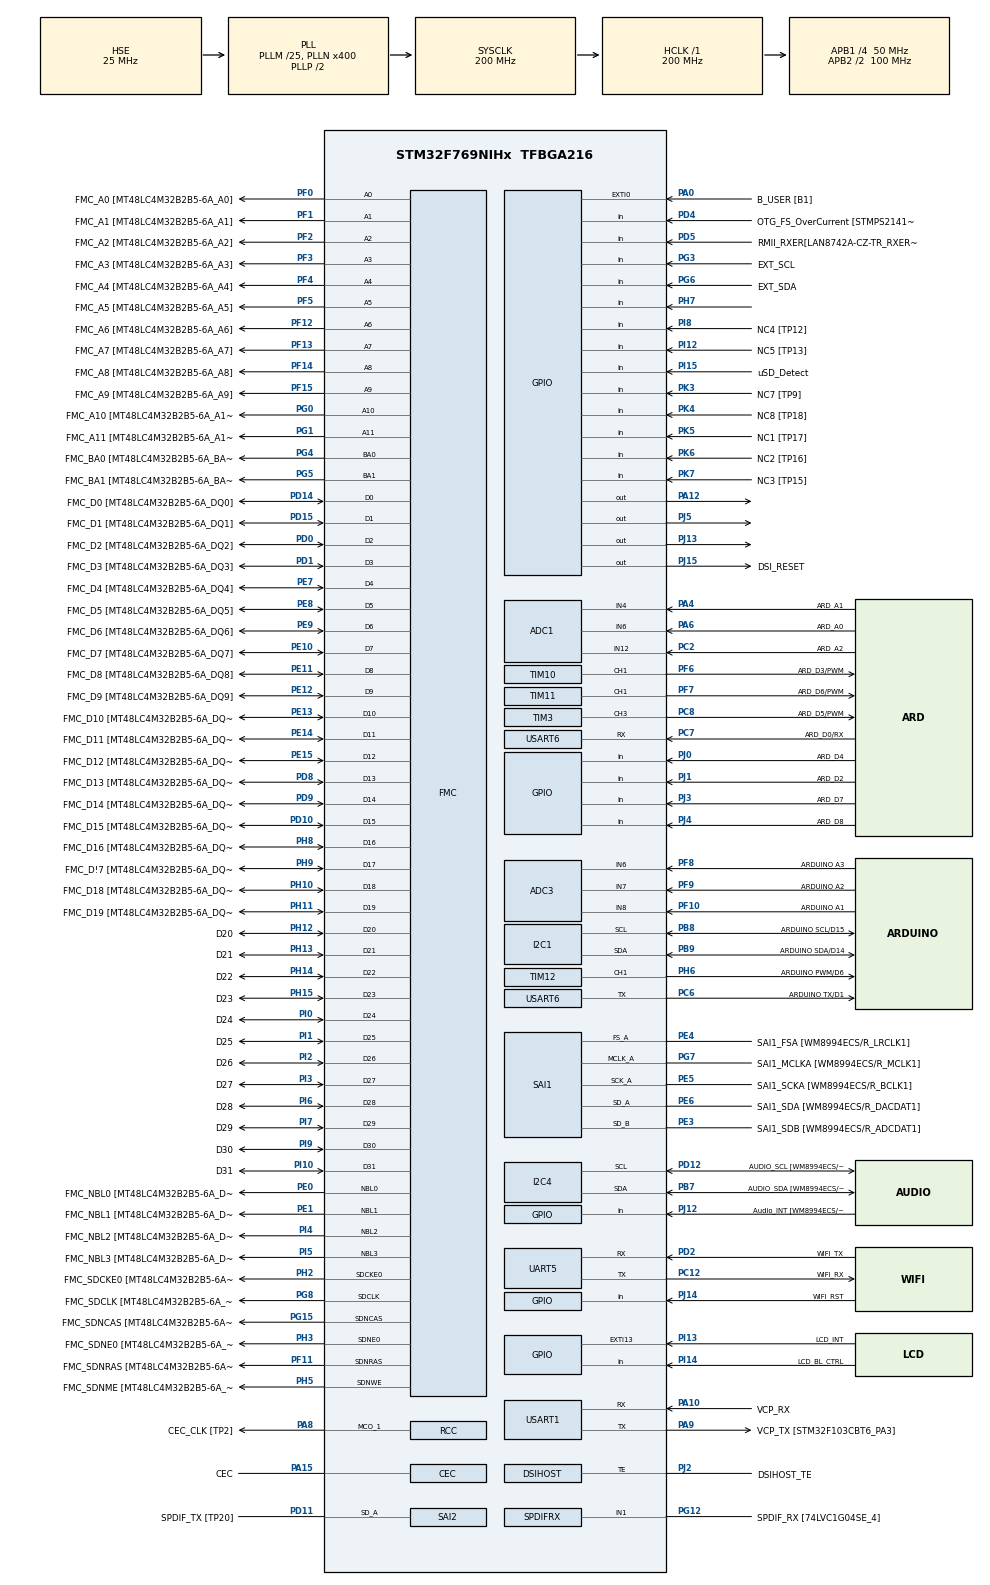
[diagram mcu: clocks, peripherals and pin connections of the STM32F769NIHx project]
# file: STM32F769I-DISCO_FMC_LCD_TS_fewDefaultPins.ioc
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PD12.GPIO_Label=AUDIO_SCL [WM8994ECS/R_SCLK]
FMC.SDClockPeriod1=FMC_SDRAM_CLOCK_PERIOD_2
SH.FMC_A0.0=FMC_A0,12b-sda1
PH15.GPIO_Label=D23
PG8.Signal=FMC_SDCLK
DSIHOST_D0N.Mode=DSIHost_Adapted_TE
PG0.Signal=FMC_A10
SAI1.Instance-SAI_A_MasterWithClock=SAI$Index_Block_A
PI15.GPIO_Label=uSD_Detect
SH.FMC_D5_DA5.0=FMC_D5,sd-32b-d1
PF10.GPIO_PuPd=GPIO_NOPULL
SH.FMC_D9_DA9.0=FMC_D9,sd-32b-d1
DSIHOST_D0P.Signal=DSIHOST_D0P
SH.FMC_D25.0=FMC_D25,sd-32b-d1
PG15.GPIO_Label=FMC_SDNCAS [MT48LC4M32B2B5-6A_CAS]
PF7.Signal=S_TIM11_CH1
NVIC.DMA2D_IRQn=true\:0\:0\:false\:false\:true\:true\:true
RCC.PLL48CLockSelection=RCC_CLK48SOURCE_PLLSAIP
SH.FMC_SDNWE.0=FMC_SDNWE,12b-sda1
PH9.Signal=FMC_D17
SH.FMC_D11_DA11.0=FMC_D11,sd-32b-d1
RTC.Alarm-AlarmA_RoutedAF=RTC_ALARM_A
RCC.APB2TimFreq_Value=200000000
PC7.Signal=USART6_RX
PD0.Signal=FMC_D2_DA2
PD8.Signal=FMC_D13_DA13
USART6.VirtualMode-Asynchronous=VM_ASYNC
PE1.Signal=FMC_NBL1
PB3.Mode=Trace_Asynchronous_SW
PF1.GPIO_Label=FMC_A1 [MT48LC4M32B2B5-6A_A1]
PI4.GPIO_Label=FMC_NBL2 [MT48LC4M32B2B5-6A_DQM2]
PK4.GPIO_Label=NC8 [TP18]
PD1.GPIO_Label=FMC_D3 [MT48LC4M32B2B5-6A_DQ3]
FMC.SelfRefreshTime1=4
PF12.GPIO_Label=FMC_A6 [MT48LC4M32B2B5-6A_A6]
LTDC.PixelFormat_L0=LTDC_PIXEL_FORMAT_RGB565
SH.S_TIM12_CH1.0=TIM12_CH1,PWM Generation1 CH1
PE9.Signal=FMC_D6_DA6
DSIHOST_D1N.Signal=DSIHOST_D1N
SH.FMC_A2.0=FMC_A2,12b-sda1
PE4.GPIO_Label=SAI1_FSA [WM8994ECS/R_LRCLK1]
PG4.GPIO_Label=FMC_BA0 [MT48LC4M32B2B5-6A_BA0]
PA8.Signal=RCC_MCO_1
SH.FMC_D1_DA1.0=FMC_D1,sd-32b-d1
LTDC.HSync=1
PJ14.Signal=GPIO_Input
PB9.Signal=I2C1_SDA
Mcu.Package=TFBGA216
PD12.Signal=I2C4_SCL
PB9.GPIO_PuPd=GPIO_NOPULL
SH.FMC_D27.0=FMC_D27,sd-32b-d1
PA10.Signal=USART1_RX
VP_RTC_VS_RTC_Calendar.Mode=RTC_Calendar
PE12.GPIO_Label=FMC_D9 [MT48LC4M32B2B5-6A_DQ9]
FMC.WriteRecoveryTime1=3
RCC.APB2CLKDivider=RCC_HCLK_DIV2
LTDC.VSync=1
RCC.APB1TimFreq_Value=100000000
PC14/OSC32_IN.GPIO_Label=RCC_OSC32_IN
PF10.Mode=IN8
FMC.RowCycleDelay1=7
DSIHOST_D1P.GPIO_Label=DSI_D1_P
PF9.GPIO_PuPd=GPIO_NOPULL
PA4.GPIO_Label=ARD_A1
PD15.Signal=FMC_D1_DA1
PJ1.GPIO_Label=ARD_D2
PG12.Signal=SPDIFRX_IN1
DSIHOST.CommandSize=400
DSIHOST.LPDcsShortWriteNoP=DSI_LP_DSW0P_ENABLE
DSIHOST.LPDcsShortReadNoP=DSI_LP_DSR0P_ENABLE
SH.FMC_A4.0=FMC_A4,12b-sda1
PK4.Signal=GPIO_Input
PH13.Signal=FMC_D21
SH.ADCx_IN6.0=ADC1_IN6,IN6
PI13.GPIO_ModeDefaultEXTI=GPIO_MODE_EVT_RISING
ADC3.Channel-IN7=ADC_CHANNEL_7
SAI1.MClockEnable-SAI_A_MasterWithClock=SAI_MASTERCLOCK_ENABLE
PG5.Signal=FMC_A15_BA1
ADC3.Channel-IN6=ADC_CHANNEL_6
SH.FMC_D10_DA10.0=FMC_D10,sd-32b-d1
ADC3.Channel-IN8=ADC_CHANNEL_8
PC2.Signal=ADCx_IN12
PI12.Signal=GPIO_Input
SAI1.ErrorAudioFreq-SAI_A_MasterWithClock=30.2 %
SH.FMC_D16.0=FMC_D16,sd-32b-d1
PF8.GPIO_Label=ARDUINO A3
LTDC.ImageWidth_L0=200
PD10.Signal=FMC_D15_DA15
PB8.GPIO_Label=ARDUINO SCL/D15
PJ3.Signal=GPIO_Input
PI8.GPIO_Label=NC4 [TP12]
PA8.GPIO_Label=CEC_CLK [TP2]
SH.FMC_D29.0=FMC_D29,sd-32b-d1
PE8.GPIO_Label=FMC_D5 [MT48LC4M32B2B5-6A_DQ5]
PH11.GPIO_Label=FMC_D19 [MT48LC4M32B2B5-6A_DQ19]
SAI1.VirtualMode-SAI_A_MasterWithClock=VM_MASTER
PC12.Mode=Asynchronous
PF10.GPIO_Mode=GPIO_MODE_ANALOG
PJ4.GPIO_Label=ARD_D8
PE1.GPIO_Label=FMC_NBL1 [MT48LC4M32B2B5-6A_DQM1]
PK7.GPIO_Label=NC3 [TP15]
PI7.Signal=FMC_D29
FMC.ReadBurst1=FMC_SDRAM_RBURST_ENABLE
SH.FMC_A6.0=FMC_A6,12b-sda1
PE14.Signal=FMC_D11_DA11
PE6.Mode=SAI_A_MasterWithClock
PG7.GPIO_Label=SAI1_MCLKA [WM8994ECS/R_MCLK1]
PI2.Signal=FMC_D26
PF4.GPIO_Label=FMC_A4 [MT48LC4M32B2B5-6A_A4]
SH.ADCx_IN4.0=ADC1_IN4,IN4
PF13.Signal=FMC_A7
PJ15.GPIO_Label=DSI_RESET
SH.FMC_NBL2.0=FMC_NBL2,Sd4ByteEnable1
SH.FMC_D18.0=FMC_D18,sd-32b-d1
PC7.GPIO_Label=ARD_D0/RX
ADC1.master=1
PE5.GPIO_Label=SAI1_SCKA [WM8994ECS/R_BCLK1]
PC12.GPIO_Label=WIFI_RX
PJ0.GPIO_Label=ARD_D4
ProjectManager.HeapSize=0x200
DSIHOST_CKP.GPIO_Label=DSI_CK_P
PH6.Signal=S_TIM12_CH1
NVIC.PriorityGroup=NVIC_PRIORITYGROUP_4
PF0.GPIO_Label=FMC_A0 [MT48LC4M32B2B5-6A_A0]
PE3.Signal=SAI1_SD_B
PC15/OSC32_OUT.Signal=RCC_OSC32_OUT
PF4.Signal=FMC_A4
DSIHOST_D0P.GPIO_Label=DSI_D0_p
PD2.Signal=UART5_RX
PI1.GPIO_Label=D25
Mcu.Family=STM32F7
LTDC.BlendingFactor1_L0=LTDC_BLENDING_FACTOR1_PAxCA
PK3.Signal=GPIO_Input
SH.FMC_A8.0=FMC_A8,12b-sda1
PC15/OSC32_OUT.GPIO_Label=RCC_OSC32_OUT
NVIC.CEC_IRQn=true\:0\:0\:false\:false\:true\:false\:true
PH14.Signal=FMC_D22
PH10.Signal=FMC_D18
SH.FMC_D14_DA14.0=FMC_D14,sd-32b-d1
PE11.GPIO_Label=FMC_D8 [MT48LC4M32B2B5-6A_DQ8]
PD0.GPIO_Label=FMC_D2 [MT48LC4M32B2B5-6A_DQ2]
PC14/OSC32_IN.Mode=LSE-External-Oscillator
SH.FMC_A14_BA0.0=FMC_BA0,FourSdramBanks1
SH.FMC_A11.0=FMC_A11,12b-sda1
PG5.GPIO_Label=FMC_BA1 [MT48LC4M32B2B5-6A_BA1]
ADC3.Channel-0\#ChannelRegularConversion=ADC_CHANNEL_6
VP_RTC_VS_RTC_Alarm_B_Intern.Mode=Alarm B
PG15.Signal=FMC_SDNCAS
PJ14.GPIO_Label=WIFI_RST
PA15.GPIO_Label=CEC
PJ2.Signal=DSIHOST_TE
SAI1.VirtualMode-SAI_B_SyncSlave=VM_SLAVE
SH.FMC_NBL1.0=FMC_NBL1,Sd4ByteEnable1
LTDC.WindowX1_L0=200
PA9.GPIO_Mode=GPIO_MODE_AF_PP
ADC1.Channel-0\#ChannelRegularConversion=ADC_CHANNEL_12
RCC.HSE_VALUE=25000000
FMC.ExitSelfRefreshDelay1=7
DSIHOST.LPGenShortWriteOneP=DSI_LP_GSW1P_ENABLE
LTDC.VBP=1
PF9.Mode=IN7
PF8.GPIO_PuPd=GPIO_NOPULL
PA14.Mode=Trace_Asynchronous_SW
DSIHOST_D1P.Signal=DSIHOST_D1P
PF11.Signal=FMC_SDNRAS
PJ12.GPIO_Label=Audio_INT [WM8994ECS/R_GPIO1]
PB7.Signal=I2C4_SDA
PB7.GPIO_Label=AUDIO_SDA [WM8994ECS/R_SDA]
PA6.Signal=ADCx_IN6
SH.S_TIM10_CH1.0=TIM10_CH1,PWM Generation1 CH1
PD5.GPIO_Label=RMII_RXER[LAN8742A-CZ-TR_RXERR]
PA15.Signal=CEC
PF8.Signal=ADC3_IN6
PG0.GPIO_Label=FMC_A10 [MT48LC4M32B2B5-6A_A10]
PI0.GPIO_Label=D24
DSIHOST_CKN.Signal=DSIHOST_CKN
PH2.Mode=SdramChipSelect1_1
PE7.Signal=FMC_D4_DA4
SH.S_TIM11_CH1.0=TIM11_CH1,PWM Generation1 CH1
PF3.GPIO_Label=FMC_A3 [MT48LC4M32B2B5-6A_A3]
DSIHOST_D0P.Mode=DSIHost_Adapted_TE
PK6.Signal=GPIO_Input
NVIC.LTDC_IRQn=true\:0\:0\:false\:false\:true\:true\:true
SH.FMC_D20.0=FMC_D20,sd-32b-d1
LTDC.VFP=1
PD15.GPIO_Label=FMC_D1 [MT48LC4M32B2B5-6A_DQ1]
LTDC.WindowY1_L0=480
PG7.Signal=SAI1_MCLK_A
PA10.Mode=Asynchronous
PH12.GPIO_Label=D20
PI14.Signal=GPIO_Input
PC8.Signal=S_TIM3_CH3
SH.FMC_D31.0=FMC_D31,sd-32b-d1
SAI2.VirtualMode-SAI_A_SPDIF=VM_SPDIF
PE14.GPIO_Label=FMC_D11 [MT48LC4M32B2B5-6A_DQ11]
PD9.Signal=FMC_D14_DA14
SH.S_TIM3_CH3.0=TIM3_CH3,PWM Generation3 CH3
PA9.GPIO_PuPd=GPIO_NOPULL
PD8.GPIO_Label=FMC_D13 [MT48LC4M32B2B5-6A_DQ13]
PG8.GPIO_Label=FMC_SDCLK [MT48LC4M32B2B5-6A_CLK]
USART1.VirtualMode-Asynchronous=VM_ASYNC
PA13.Signal=SYS_JTMS-SWDIO
SAI1.RealAudioFreq-SAI_A_MasterWithClock=250.0 KHz
PA9.Mode=Asynchronous
PF6.Signal=S_TIM10_CH1
SH.FMC_D13_DA13.0=FMC_D13,sd-32b-d1
PH8.Signal=FMC_D16
PB9.Mode=I2C
RCC.SDMMC2ClockSelection=RCC_SDMMC2CLKSOURCE_CLK48
RCC.USBFreq_Value=48000000
PF9.GPIO_Label=ARDUINO A2
PD10.GPIO_Label=FMC_D15 [MT48LC4M32B2B5-6A_DQ15]
PD2.Mode=Asynchronous
DSIHOST_CKP.Signal=DSIHOST_CKP
board=STM32F769I-DISCO
PG12.Mode=IN1
RCC.VCOOutputFreq_Value=400000000
DSIHOST.LPDcsLongWrite=DSI_LP_DLW_ENABLE
PI9.Signal=FMC_D30
TIM12.Channel-PWM\ Generation1\ CH1=TIM_CHANNEL_1
SH.FMC_D22.0=FMC_D22,sd-32b-d1
PI13.GPIO_Label=LCD_INT
SAI2.Instance-SAI_A_SPDIF=SAI$Index_Block_A
PI4.Signal=FMC_NBL2
PE5.Mode=SAI_A_MasterWithClock
SH.FMC_D12_DA12.0=FMC_D12,sd-32b-d1
PF15.GPIO_Label=FMC_A9 [MT48LC4M32B2B5-6A_A9]
DSIHOST.LPGenShortWriteTwoP=DSI_LP_GSW2P_ENABLE
PF1.Signal=FMC_A1
PF8.GPIO_Mode=GPIO_MODE_ANALOG
PJ0.Signal=GPIO_Input
PE0.Signal=FMC_NBL0
PE7.GPIO_Label=FMC_D4 [MT48LC4M32B2B5-6A_DQ4]
PE12.Signal=FMC_D9_DA9
SAI2.RealAudioFreq-SAI_A_SPDIF=1000.0 KHz
DSIHOST_CKN.GPIO_Label=DSI_CK_N
RCC.SYSCLKFreq_VALUE=200000000
DSIHOST.LPGenShortReadNoP=DSI_LP_GSR0P_ENABLE
PJ5.Signal=GPIO_Output
PD11.Mode=SAI_A_SPDIF
RCC.HSI_VALUE=16000000
PH0/OSC_IN.GPIO_Label=OSC_25M [NZ2520SB-25.00M_OUT]
PF9.GPIO_Mode=GPIO_MODE_ANALOG
RCC.PLLQ=4
PI3.GPIO_Label=D27
PH3.Signal=FMC_SDNE0
RCC.PLLM=25
RCC.PLLN=400
DSIHOST.StopWaitTime=10
TIM11.Channel=TIM_CHANNEL_1
PA9.GPIO_Speed=GPIO_SPEED_FREQ_LOW
CORTEX_M7.CPU_DCache=Enabled
PB8.GPIO_Speed=GPIO_SPEED_FREQ_LOW
PJ2.GPIO_Label=DSIHOST_TE
VP_CRC_VS_CRC.Mode=CRC_Activate
LTDC.ImageHeight_L0=480
PJ13.Signal=GPIO_Output
SH.FMC_D7_DA7.0=FMC_D7,sd-32b-d1
RTC.Alarm_B-Alarm\ B=RTC_ALARM_B
PK5.Signal=GPIO_Input
SH.FMC_D24.0=FMC_D24,sd-32b-d1
PH12.Signal=FMC_D20
FMC.RCDDelay1=2
PG4.Signal=FMC_A14_BA0
PC12.Signal=UART5_TX
PA14.GPIO_Label=SWCLK
PG6.GPIO_Label=EXT_SDA
PH6.GPIO_Label=ARDUINO PWM/D6
FMC.LoadToActiveDelay1=2
PK6.GPIO_Label=NC2 [TP16]
DSIHOST_D1P.Mode=DSIHost_Adapted_TE
PC6.GPIO_Label=ARDUINO TX/D1
VP_RTC_VS_RTC_Activate.Mode=RTC_Enabled
PI6.GPIO_Label=D28
PA6.GPIO_Label=ARD_A0
PE6.GPIO_Label=SAI1_SDA [WM8994ECS/R_DACDAT1]
PF6.GPIO_Label=ARD_D3/PWM
RCC.SYSCLKSource=RCC_SYSCLKSOURCE_PLLCLK
SH.FMC_A15_BA1.0=FMC_BA1,FourSdramBanks1
PH5.Signal=FMC_SDNWE
I2C4.Timing=0x00C0EAFF
PD4.Signal=GPIO_Input
VP_TIM10_VS_ClockSourceINT.Mode=Enable_Timer
DSIHOST_CKP.Mode=DSIHost_Adapted_TE
PH1/OSC_OUT.Signal=RCC_OSC_OUT
PE5.Signal=SAI1_SCK_A
PF10.GPIO_Label=ARDUINO A1
PH10.GPIO_Label=FMC_D18 [MT48LC4M32B2B5-6A_DQ18]
DSIHOST.LPDcsShortWriteOneP=DSI_LP_DSW1P_ENABLE
TIM10.Channel=TIM_CHANNEL_1
DSIHOST.LPGenShortReadTwoP=DSI_LP_GSR2P_ENABLE
SH.FMC_D26.0=FMC_D26,sd-32b-d1
PJ2.Mode=DSIHost_Adapted_TE
PI6.Signal=FMC_D28
PI3.Signal=FMC_D27
PF8.Mode=IN6
PF3.Signal=FMC_A3
PE10.Signal=FMC_D7_DA7
VP_TIM1_VS_ClockSourceINT.Mode=Internal
ADC1.SamplingTime-0\#ChannelRegularConversion=ADC_SAMPLETIME_3CYCLES
DSIHOST_D1N.GPIO_Label=DSI_D1_N
PJ4.Signal=GPIO_Input
SH.FMC_A1.0=FMC_A1,12b-sda1
PH2.Signal=FMC_SDCKE0
SH.FMC_SDCLK.0=FMC_SDCLK,12b-sda1
PF14.Signal=FMC_A8
VP_DMA2D_VS_DMA2D.Mode=DMA2D_Activate
PE10.GPIO_Label=FMC_D7 [MT48LC4M32B2B5-6A_DQ7]
SH.FMC_D3_DA3.0=FMC_D3,sd-32b-d1
PI10.GPIO_Label=D31
PH15.Signal=FMC_D23
ADC1.Rank-0\#ChannelRegularConversion=1
SH.FMC_D28.0=FMC_D28,sd-32b-d1
PD9.GPIO_Label=FMC_D14 [MT48LC4M32B2B5-6A_DQ14]
PA9.GPIO_Label=VCP_TX [STM32F103CBT6_PA3]
PB8.GPIO_PuPd=GPIO_NOPULL
PC6.Signal=USART6_TX
PD1.Signal=FMC_D3_DA3
PF14.GPIO_Label=FMC_A8 [MT48LC4M32B2B5-6A_A8]
RCC.APB1CLKDivider=RCC_HCLK_DIV4
PF13.GPIO_Label=FMC_A7 [MT48LC4M32B2B5-6A_A7]
TIM3.Channel-PWM\ Generation3\ CH3=TIM_CHANNEL_3
SH.FMC_A3.0=FMC_A3,12b-sda1
FMC.CASLatency1=FMC_SDRAM_CAS_LATENCY_3
SH.FMC_D15_DA15.0=FMC_D15,sd-32b-d1
PC6.Mode=Asynchronous
PA9.Signal=USART1_TX
I2C1.Timing=0x00C0EAFF
PE9.GPIO_Label=FMC_D6 [MT48LC4M32B2B5-6A_DQ6]
SH.FMC_D17.0=FMC_D17,sd-32b-d1
PJ15.Signal=GPIO_Output
PH9.GPIO_Label=FMC_D\!7 [MT48LC4M32B2B5-6A_DQ17]
PI9.GPIO_Label=D30
PE15.Signal=FMC_D12_DA12
PE8.Signal=FMC_D5_DA5
PI1.Signal=FMC_D25
PA0/WKUP.GPIO_Label=B_USER [B1]
SH.FMC_SDNCAS.0=FMC_SDNCAS,12b-sda1
PA13.Mode=Trace_Asynchronous_SW
PH14.GPIO_Label=D22
PA4.Signal=ADCx_IN4
PD12.Mode=I2C
PE13.GPIO_Label=FMC_D10 [MT48LC4M32B2B5-6A_DQ10]
PD11.Signal=SAI2_SD_A
SH.FMC_A5.0=FMC_A5,12b-sda1
LTDC.Alpha_L0=255
PK3.GPIO_Label=NC7 [TP9]
PF9.Signal=ADC3_IN7
SAI2.Synchro-SAI_A_SPDIF=SAI_ASYNCHRONOUS
PB8.Mode=I2C
DSIHOST.LPMaxReadPacket=DSI_LP_MRDP_ENABLE
PA8.Mode=Clock-out-1
SH.FMC_NBL3.0=FMC_NBL3,Sd4ByteEnable1
PG3.GPIO_Label=EXT_SCL
SH.FMC_D19.0=FMC_D19,sd-32b-d1
PD2.GPIO_Label=WIFI_TX
PH2.GPIO_Label=FMC_SDCKE0 [MT48LC4M32B2B5-6A_CKE]
PK7.Signal=GPIO_Input
RCC.CortexFreq_Value=200000000
PG6.Signal=GPIO_Input
LTDC.HBP=1
SH.FMC_NBL0.0=FMC_NBL0,Sd4ByteEnable1
DSIHOST.LPGenShortWriteNoP=DSI_LP_GSW0P_ENABLE
SH.FMC_D6_DA6.0=FMC_D6,sd-32b-d1
PA0/WKUP.Signal=GPXTI0
PH5.GPIO_Label=FMC_SDNME [MT48LC4M32B2B5-6A_WE]
PI5.GPIO_Label=FMC_NBL3 [MT48LC4M32B2B5-6A_DQM3]
PK5.GPIO_Label=NC1 [TP17]
PI14.GPIO_Label=LCD_BL_CTRL
ProjectManager.StackSize=0x400
PH3.Mode=SdramChipSelect1_1
SH.FMC_A7.0=FMC_A7,12b-sda1
PA12.Signal=GPIO_Output
PH0/OSC_IN.Mode=HSE-External-Oscillator
PD11.GPIO_Label=SPDIF_TX [TP20]
RCC.HCLKFreq_Value=200000000
PF11.GPIO_Label=FMC_SDNRAS [MT48LC4M32B2B5-6A_RAS]
PF12.Signal=FMC_A6
PI13.Signal=GPXTI13
SH.FMC_A10.0=FMC_A10,12b-sda1
RCC.AHBFreq_Value=200000000
DSIHOST_D1N.Mode=DSIHost_Adapted_TE
SH.FMC_D8_DA8.0=FMC_D8,sd-32b-d1
FMC.RPDelay1=2
PA15.Mode=CEC_Activate
PI8.Signal=GPIO_Input
SH.FMC_D2_DA2.0=FMC_D2,sd-32b-d1
PE13.Signal=FMC_D10_DA10
NVIC.DSI_IRQn=true\:0\:0\:false\:false\:true\:true\:true
PF7.GPIO_Label=ARD_D6/PWM
PI5.Signal=FMC_NBL3
PI0.Signal=FMC_D24
PA10.GPIO_Label=VCP_RX 
LTDC.HFP=1
LTDC.BlendingFactor2_L0=LTDC_BLENDING_FACTOR2_PAxCA
PE4.Mode=SAI_A_MasterWithClock
SH.FMC_SDNRAS.0=FMC_SDNRAS,12b-sda1
LTDC.ActiveW=200
PE4.Signal=SAI1_FS_A
PH1/OSC_OUT.Mode=HSE-External-Oscillator
SH.FMC_D0_DA0.0=FMC_D0,sd-32b-d1
PJ12.Signal=GPIO_Input
PC14/OSC32_IN.Signal=RCC_OSC32_IN
PF5.GPIO_Label=FMC_A5 [MT48LC4M32B2B5-6A_A5]
SH.FMC_A9.0=FMC_A9,12b-sda1
PJ1.Signal=GPIO_Input
SH.FMC_D4_DA4.0=FMC_D4,sd-32b-d1
PI12.GPIO_Label=NC5 [TP13]
PE0.GPIO_Label=FMC_NBL0 [MT48LC4M32B2B5-6A_DQM0]
ADC3.ClockPrescaler=ADC_CLOCK_SYNC_PCLK_DIV4
PH3.GPIO_Label=FMC_SDNE0 [MT48LC4M32B2B5-6A_CS]
PF5.Signal=FMC_A5
RCC.PLLSAIP=RCC_PLLSAIP_DIV4
PH7.Signal=GPIO_Input
RCC.PLLSAIQ=3
PB9.GPIO_Speed=GPIO_SPEED_FREQ_LOW
PJ3.GPIO_Label=ARD_D7
SH.FMC_D30.0=FMC_D30,sd-32b-d1
PF0.Signal=FMC_A0
PI2.GPIO_Label=D26
DSIHOST.TEAcknowledgeRequest=DSI_TE_ACKNOWLEDGE_ENABLE
PE3.Mode=SAI_B_SyncSlave
PC2.GPIO_Label=ARD_A2
RCC.PLLSourceVirtual=RCC_PLLSOURCE_HSE
LTDC.FBStartAdress_L0=0xC0000000
CORTEX_M7.CPU_ICache=Enabled
PB9.GPIO_Label=ARDUINO SDA/D14
PH11.Signal=FMC_D19
PG3.Signal=GPIO_Input
PG1.Signal=FMC_A11
DSIHOST.LPGenLongWrite=DSI_LP_GLW_ENABLE
PI10.Signal=FMC_D31
PD5.Signal=GPIO_Input
VP_TIM11_VS_ClockSourceINT.Mode=Enable_Timer
PH13.GPIO_Label=D21
PC8.GPIO_Label=ARD_D5/PWM
SH.FMC_D21.0=FMC_D21,sd-32b-d1
PH8.GPIO_Label=FMC_D16 [MT48LC4M32B2B5-6A_DQ16]
SH.ADCx_IN12.0=ADC1_IN12,IN12
PE15.GPIO_Label=FMC_D12 [MT48LC4M32B2B5-6A_DQ12]
ProjectManager.TargetToolchain=STM32CubeIDE
PF2.Signal=FMC_A2
PG7.Mode=SAI_A_MasterWithClock
PE11.Signal=FMC_D8_DA8
PG1.GPIO_Label=FMC_A11 [MT48LC4M32B2B5-6A_A11]
PB9.GPIO_Mode=GPIO_MODE_AF_OD
DSIHOST.NumberOfLanes=DSI_TWO_DATA_LANES
PH0/OSC_IN.Signal=RCC_OSC_IN
RCC.APB2Freq_Value=100000000
LTDC.Layers=0
PD4.GPIO_Label=OTG_FS_OverCurrent [STMPS2141STR_Fault]
PF10.Signal=ADC3_IN8
PI7.GPIO_Label=D29
PF15.Signal=FMC_A9
PD14.GPIO_Label=FMC_D0 [MT48LC4M32B2B5-6A_DQ0]
PE6.Signal=SAI1_SD_A
Mcu.Name=STM32F769NIHx
PA13.GPIO_Label=SWDIO
DSIHOST_CKN.Mode=DSIHost_Adapted_TE
DSIHOST_D0N.GPIO_Label=DSI_D0_N
PD14.Signal=FMC_D0_DA0
PB3.Signal=SYS_JTDO-SWO
PC15/OSC32_OUT.Mode=LSE-External-Oscillator
SH.FMC_D23.0=FMC_D23,sd-32b-d1
SAI1.Instance-SAI_B_SyncSlave=SAI$Index_Block_B
PB7.Mode=I2C
PA14.Signal=SYS_JTCK-SWCLK
DSIHOST_D0N.Signal=DSIHOST_D0N
PG12.GPIO_Label=SPDIF_RX [74LVC1G04SE_4]
VP_LTDC_DSIMode.Mode=RGB888
ADC1.NbrOfConversionFlag=1
PI15.Signal=GPIO_Input
PB8.Signal=I2C1_SCL
PE3.GPIO_Label=SAI1_SDB [WM8994ECS/R_ADCDAT1]
DSIHOST.LPGenShortReadOneP=DSI_LP_GSR1P_ENABLE
PC7.Mode=Asynchronous
PB8.GPIO_Mode=GPIO_MODE_AF_OD
RCC.APB1Freq_Value=50000000
ADC1.ClockPrescaler=ADC_CLOCK_SYNC_PCLK_DIV4
DMA2D.Mode=DMA2D_R2M
PF2.GPIO_Label=FMC_A2 [MT48LC4M32B2B5-6A_A2]

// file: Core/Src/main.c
/* USER CODE BEGIN Header */
/**
  ******************************************************************************
  * @file           : main.c
  * @brief          : Main program body
  ******************************************************************************
  * @attention
  *
  * <h2><center>&copy; Copyright (c) 2021 STMicroelectronics.
  * All rights reserved.</center></h2>
  *
  * This software component is licensed by ST under Ultimate Liberty license
  * SLA0044, the "License"; You may not use this file except in compliance with
  * the License. You may obtain a copy of the License at:
  *                             www.st.com/SLA0044
  *
  ******************************************************************************
  */
/* USER CODE END Header */
#include "main.h"

/* USER CODE BEGIN Includes */

#include "stlogo.h"

/* USER CODE END Includes */

/* USER CODE BEGIN PD */

#define BUFFER_SIZE         ((uint32_t)0x1000)
#define WRITE_READ_ADDR     ((uint32_t)0x0800)
#define SDRAM_WRITE_READ_ADDR        ((uint32_t)0xC0177000)

#define  CIRCLE_RADIUS        40
#define  LINE_LENGHT          30

/* USER CODE END PD */

/* USER CODE BEGIN PM */

#define CIRCLE_XPOS(i)  	((i * BSP_LCD_GetXSize()) / 5)
#define CIRCLE_YPOS(i)  	(BSP_LCD_GetYSize() - CIRCLE_RADIUS - 60)
#define LCD_FEATURES_NUM	3

/* USER CODE END PM */

CRC_HandleTypeDef hcrc;

DMA2D_HandleTypeDef hdma2d;

DSI_HandleTypeDef hdsi;

CEC_HandleTypeDef hcec;

I2C_HandleTypeDef hi2c1;
I2C_HandleTypeDef hi2c4;

LTDC_HandleTypeDef hltdc;

RTC_HandleTypeDef hrtc;

SAI_HandleTypeDef hsai_BlockA1;
SAI_HandleTypeDef hsai_BlockB1;
SAI_HandleTypeDef hsai_BlockA2;

SPDIFRX_HandleTypeDef hspdif;

TIM_HandleTypeDef htim1;
TIM_HandleTypeDef htim3;
TIM_HandleTypeDef htim10;
TIM_HandleTypeDef htim11;
TIM_HandleTypeDef htim12;

UART_HandleTypeDef huart5;
UART_HandleTypeDef huart1;
UART_HandleTypeDef huart6;

SDRAM_HandleTypeDef hsdram1;

uint8_t cec_receive_buffer[16];
/* USER CODE BEGIN PV */

SDRAM_HandleTypeDef      sdramHandle;
FMC_SDRAM_TimingTypeDef  Timing;
FMC_SDRAM_CommandTypeDef command;

/* Read/Write Buffers */
uint32_t aTxBuffer[BUFFER_SIZE];
uint32_t aRxBuffer[BUFFER_SIZE];

/* Status variables */
__IO uint32_t uwWriteReadStatus = 0;

TS_StateTypeDef  TS_State = {0};

/* Counter index */
uint32_t uwIndex = 0;

typedef enum
{
  TOUCHSCREEN_DEMO_1 = 1,
  TOUCHSCREEN_DEMO_2 = 2,
  TOUCHSCREEN_DEMO_3 = 3,
  TOUCHSCREEN_DEMO_MAX = TOUCHSCREEN_DEMO_3,

} TouchScreenDemoTypeDef;

/* USER CODE END PV */

void SystemClock_Config(void);
static void MX_GPIO_Init(void);
static void MX_ADC1_Init(void);
static void MX_ADC3_Init(void);
static void MX_CRC_Init(void);
static void MX_DMA2D_Init(void);
static void MX_DSIHOST_DSI_Init(void);
static void MX_FMC_Init(void);
static void MX_HDMI_CEC_Init(void);
static void MX_I2C1_Init(void);
static void MX_I2C4_Init(void);
static void MX_LTDC_Init(void);
static void MX_RTC_Init(void);
static void MX_SAI1_Init(void);
static void MX_SAI2_Init(void);
static void MX_SPDIFRX_Init(void);
static void MX_TIM1_Init(void);
static void MX_TIM3_Init(void);
static void MX_TIM10_Init(void);
static void MX_TIM11_Init(void);
static void MX_TIM12_Init(void);
static void MX_UART5_Init(void);
static void MX_USART1_UART_Init(void);
static void MX_USART6_UART_Init(void);
/* USER CODE BEGIN PFP */

//static void BSP_SDRAM_Initialization_Sequence(SDRAM_HandleTypeDef *hsdram, FMC_SDRAM_CommandTypeDef *Command);
static void Fill_Buffer(uint32_t *pBuffer, uint32_t uwBufferLenght, uint32_t uwOffset);

static void Display_DemoDescription(void);
static void LCD_SetHint(void);
static void LCD_Show_Feature(uint8_t feature);
void Touchscreen_demo1(void);
uint8_t TouchScreen_GetTouchPosition(void);
void Touchscreen_DrawBackground_Circles(uint8_t state);
static void Touchscreen_SetHint_Demo(TouchScreenDemoTypeDef demoIndex);
uint8_t CheckForUserInput(void);

/* USER CODE END PFP */

int main(void)
{
  /* USER CODE BEGIN 1 */

	uint8_t  lcd_status = LCD_OK;

  /* USER CODE END 1 */

  /* Enable I-Cache---------------------------------------------------------*/
  SCB_EnableICache();

  /* Enable D-Cache---------------------------------------------------------*/
  SCB_EnableDCache();

  /* MCU Configuration--------------------------------------------------------*/

  /* Reset of all peripherals, Initializes the Flash interface and the Systick. */
  HAL_Init();

  /* Configure the system clock */
  SystemClock_Config();

  /* Initialize all configured peripherals */
  MX_GPIO_Init();
  MX_ADC1_Init();
  MX_ADC3_Init();
  MX_CRC_Init();
  MX_DMA2D_Init();
  MX_DSIHOST_DSI_Init();
  MX_FMC_Init();
  MX_HDMI_CEC_Init();
  MX_I2C1_Init();
  MX_I2C4_Init();
  MX_LTDC_Init();
  MX_RTC_Init();
  MX_SAI1_Init();
  MX_SAI2_Init();
  MX_SPDIFRX_Init();
  MX_TIM1_Init();
  MX_TIM3_Init();
  MX_TIM10_Init();
  MX_TIM11_Init();
  MX_TIM12_Init();
  MX_UART5_Init();
  MX_USART1_UART_Init();
  MX_USART6_UART_Init();
  /* USER CODE BEGIN 2 */

  /* SDRAM initialization sequence */
  sdramHandle.Instance = FMC_SDRAM_DEVICE; // NEED this if BSP_SDRAM_Init(void) is not called! and needed in BSP_SDRAM_Initialization_sequence
  BSP_SDRAM_Initialization_sequence(REFRESH_COUNT);

  /*##-2- SDRAM memory read/write access #####################################*/

  /* Fill the buffer to write */
  Fill_Buffer(aTxBuffer, BUFFER_SIZE, 0xA244250F);

  /* Write data to the SDRAM memory */
  for (uwIndex = 0; uwIndex < BUFFER_SIZE; uwIndex++)
  {
    *(__IO uint32_t*) (SDRAM_WRITE_READ_ADDR + WRITE_READ_ADDR + 4*uwIndex) = aTxBuffer[uwIndex];
  }

  /* Read back data from the SDRAM memory */
  for (uwIndex = 0; uwIndex < BUFFER_SIZE; uwIndex++)
  {
    aRxBuffer[uwIndex] = *(__IO uint32_t*) (SDRAM_WRITE_READ_ADDR + WRITE_READ_ADDR + 4*uwIndex);
  }

  /*##-3- Checking data integrity ############################################*/

  for (uwIndex = 0; (uwIndex < BUFFER_SIZE) && (uwWriteReadStatus == 0); uwIndex++)
  {
    if (aRxBuffer[uwIndex] != aTxBuffer[uwIndex])
    {
      uwWriteReadStatus++;
    }
  }

  if (uwWriteReadStatus != 0)
  {
    while(1)
    {
      /* KO, Toggle LED1 with a period of 200 ms */
      HAL_GPIO_TogglePin(GPIOJ, GPIO_PIN_13); // RED
      HAL_Delay(200);
    }
  }

  /* Initialize the LCD */
  lcd_status = BSP_LCD_Init();
  while(lcd_status != LCD_OK);

  BSP_LCD_LayerDefaultInit(0, LCD_FB_START_ADDRESS);

  BSP_LCD_Clear(LCD_COLOR_WHITE);
  Display_DemoDescription();

  HAL_Delay(5000);

  LCD_SetHint();

  HAL_Delay(5000);

  for (uint8_t feature; feature < LCD_FEATURES_NUM; feature++)
  {
	  LCD_Show_Feature(feature);
	  HAL_Delay(2000);
  }

//  BSP_LCD_Reset();

  Touchscreen_demo1();

  HAL_GPIO_TogglePin(GPIOA, GPIO_PIN_12); // GRN

  /* USER CODE END 2 */

  /* Infinite loop */
  /* USER CODE BEGIN WHILE */
  while (1)
  {
//	  HAL_GPIO_TogglePin(GPIOJ, GPIO_PIN_5); // GRN
//	  HAL_GPIO_TogglePin(GPIOA, GPIO_PIN_12); // GRN
//	  HAL_GPIO_TogglePin(GPIOJ, GPIO_PIN_13); // RED
//	  HAL_Delay(200);
    /* USER CODE END WHILE */

  }
}

void SystemClock_Config(void)
{
  RCC_OscInitTypeDef RCC_OscInitStruct = {0};
  RCC_ClkInitTypeDef RCC_ClkInitStruct = {0};
  RCC_PeriphCLKInitTypeDef PeriphClkInitStruct = {0};

  /** Configure LSE Drive Capability
  */
  HAL_PWR_EnableBkUpAccess();
  /** Configure the main internal regulator output voltage
  */
  __HAL_RCC_PWR_CLK_ENABLE();
  __HAL_PWR_VOLTAGESCALING_CONFIG(PWR_REGULATOR_VOLTAGE_SCALE1);
  /** Initializes the RCC Oscillators according to the specified parameters
  * in the RCC_OscInitTypeDef structure.
  */
  RCC_OscInitStruct.OscillatorType = RCC_OSCILLATORTYPE_HSI|RCC_OSCILLATORTYPE_LSI
                              |RCC_OSCILLATORTYPE_HSE;
  RCC_OscInitStruct.HSEState = RCC_HSE_ON;
  RCC_OscInitStruct.HSIState = RCC_HSI_ON;
  RCC_OscInitStruct.HSICalibrationValue = RCC_HSICALIBRATION_DEFAULT;
  RCC_OscInitStruct.LSIState = RCC_LSI_ON;
  RCC_OscInitStruct.PLL.PLLState = RCC_PLL_ON;
  RCC_OscInitStruct.PLL.PLLSource = RCC_PLLSOURCE_HSE;
  RCC_OscInitStruct.PLL.PLLM = 25;
  RCC_OscInitStruct.PLL.PLLN = 400;
  RCC_OscInitStruct.PLL.PLLP = RCC_PLLP_DIV2;
  RCC_OscInitStruct.PLL.PLLQ = 4;
  if (HAL_RCC_OscConfig(&RCC_OscInitStruct) != HAL_OK)
  {
    Error_Handler();
  }
  /** Activate the Over-Drive mode
  */
  if (HAL_PWREx_EnableOverDrive() != HAL_OK)
  {
    Error_Handler();
  }
  /** Initializes the CPU, AHB and APB buses clocks
  */
  RCC_ClkInitStruct.ClockType = RCC_CLOCKTYPE_HCLK|RCC_CLOCKTYPE_SYSCLK
                              |RCC_CLOCKTYPE_PCLK1|RCC_CLOCKTYPE_PCLK2;
  RCC_ClkInitStruct.SYSCLKSource = RCC_SYSCLKSOURCE_PLLCLK;
  RCC_ClkInitStruct.AHBCLKDivider = RCC_SYSCLK_DIV1;
  RCC_ClkInitStruct.APB1CLKDivider = RCC_HCLK_DIV4;
  RCC_ClkInitStruct.APB2CLKDivider = RCC_HCLK_DIV2;

  if (HAL_RCC_ClockConfig(&RCC_ClkInitStruct, FLASH_LATENCY_6) != HAL_OK)
  {
    Error_Handler();
  }
  PeriphClkInitStruct.PeriphClockSelection = RCC_PERIPHCLK_SPDIFRX|RCC_PERIPHCLK_LTDC
                              |RCC_PERIPHCLK_RTC|RCC_PERIPHCLK_USART1
                              |RCC_PERIPHCLK_USART6|RCC_PERIPHCLK_UART5
                              |RCC_PERIPHCLK_SAI1|RCC_PERIPHCLK_SAI2
                              |RCC_PERIPHCLK_I2C1|RCC_PERIPHCLK_I2C4
                              |RCC_PERIPHCLK_CEC;
  PeriphClkInitStruct.PLLI2S.PLLI2SN = 192;
  PeriphClkInitStruct.PLLI2S.PLLI2SP = RCC_PLLP_DIV2;
  PeriphClkInitStruct.PLLI2S.PLLI2SR = 2;
  PeriphClkInitStruct.PLLI2S.PLLI2SQ = 2;
  PeriphClkInitStruct.PLLSAI.PLLSAIN = 192;
  PeriphClkInitStruct.PLLSAI.PLLSAIR = 2;
  PeriphClkInitStruct.PLLSAI.PLLSAIQ = 3;
  PeriphClkInitStruct.PLLSAI.PLLSAIP = RCC_PLLSAIP_DIV4;
  PeriphClkInitStruct.PLLI2SDivQ = 1;
  PeriphClkInitStruct.PLLSAIDivQ = 1;
  PeriphClkInitStruct.PLLSAIDivR = RCC_PLLSAIDIVR_2;
  PeriphClkInitStruct.RTCClockSelection = RCC_RTCCLKSOURCE_LSI;
  PeriphClkInitStruct.Sai1ClockSelection = RCC_SAI1CLKSOURCE_PLLSAI;
  PeriphClkInitStruct.Sai2ClockSelection = RCC_SAI2CLKSOURCE_PLLSAI;
  PeriphClkInitStruct.Usart1ClockSelection = RCC_USART1CLKSOURCE_PCLK2;
  PeriphClkInitStruct.Uart5ClockSelection = RCC_UART5CLKSOURCE_PCLK1;
  PeriphClkInitStruct.Usart6ClockSelection = RCC_USART6CLKSOURCE_PCLK2;
  PeriphClkInitStruct.I2c1ClockSelection = RCC_I2C1CLKSOURCE_PCLK1;
  PeriphClkInitStruct.I2c4ClockSelection = RCC_I2C4CLKSOURCE_PCLK1;
  PeriphClkInitStruct.CecClockSelection = RCC_CECCLKSOURCE_HSI;
  if (HAL_RCCEx_PeriphCLKConfig(&PeriphClkInitStruct) != HAL_OK)
  {
    Error_Handler();
  }
  HAL_RCC_MCOConfig(RCC_MCO1, RCC_MCO1SOURCE_HSI, RCC_MCODIV_1);
}

static void MX_ADC1_Init(void)
{

  LL_ADC_InitTypeDef ADC_InitStruct = {0};
  LL_ADC_REG_InitTypeDef ADC_REG_InitStruct = {0};
  LL_ADC_CommonInitTypeDef ADC_CommonInitStruct = {0};

  LL_GPIO_InitTypeDef GPIO_InitStruct = {0};

  /* Peripheral clock enable */
  LL_APB2_GRP1_EnableClock(LL_APB2_GRP1_PERIPH_ADC1);

  LL_AHB1_GRP1_EnableClock(LL_AHB1_GRP1_PERIPH_GPIOC);
  LL_AHB1_GRP1_EnableClock(LL_AHB1_GRP1_PERIPH_GPIOA);
  /**ADC1 GPIO Configuration
  PC2   ------> ADC1_IN12
  PA4   ------> ADC1_IN4
  PA6   ------> ADC1_IN6
  */
  GPIO_InitStruct.Pin = LL_GPIO_PIN_2;
  GPIO_InitStruct.Mode = LL_GPIO_MODE_ANALOG;
  GPIO_InitStruct.Pull = LL_GPIO_PULL_NO;
  LL_GPIO_Init(GPIOC, &GPIO_InitStruct);

  GPIO_InitStruct.Pin = LL_GPIO_PIN_4;
  GPIO_InitStruct.Mode = LL_GPIO_MODE_ANALOG;
  GPIO_InitStruct.Pull = LL_GPIO_PULL_NO;
  LL_GPIO_Init(GPIOA, &GPIO_InitStruct);

  GPIO_InitStruct.Pin = LL_GPIO_PIN_6;
  GPIO_InitStruct.Mode = LL_GPIO_MODE_ANALOG;
  GPIO_InitStruct.Pull = LL_GPIO_PULL_NO;
  LL_GPIO_Init(GPIOA, &GPIO_InitStruct);

  /** Common config
  */
  ADC_InitStruct.Resolution = LL_ADC_RESOLUTION_12B;
  ADC_InitStruct.DataAlignment = LL_ADC_DATA_ALIGN_RIGHT;
  ADC_InitStruct.SequencersScanMode = LL_ADC_SEQ_SCAN_DISABLE;
  LL_ADC_Init(ADC1, &ADC_InitStruct);
  ADC_REG_InitStruct.TriggerSource = LL_ADC_REG_TRIG_SOFTWARE;
  ADC_REG_InitStruct.SequencerLength = LL_ADC_REG_SEQ_SCAN_DISABLE;
  ADC_REG_InitStruct.SequencerDiscont = LL_ADC_REG_SEQ_DISCONT_DISABLE;
  ADC_REG_InitStruct.ContinuousMode = LL_ADC_REG_CONV_SINGLE;
  ADC_REG_InitStruct.DMATransfer = LL_ADC_REG_DMA_TRANSFER_NONE;
  LL_ADC_REG_Init(ADC1, &ADC_REG_InitStruct);
  LL_ADC_REG_SetFlagEndOfConversion(ADC1, LL_ADC_REG_FLAG_EOC_UNITARY_CONV);
  ADC_CommonInitStruct.CommonClock = LL_ADC_CLOCK_SYNC_PCLK_DIV4;
  ADC_CommonInitStruct.Multimode = LL_ADC_MULTI_INDEPENDENT;
  LL_ADC_CommonInit(__LL_ADC_COMMON_INSTANCE(ADC1), &ADC_CommonInitStruct);
  /** Configure Regular Channel
  */
  LL_ADC_REG_SetSequencerRanks(ADC1, LL_ADC_REG_RANK_1, LL_ADC_CHANNEL_12);
  LL_ADC_SetChannelSamplingTime(ADC1, LL_ADC_CHANNEL_12, LL_ADC_SAMPLINGTIME_3CYCLES);

}

static void MX_ADC3_Init(void)
{

  LL_ADC_InitTypeDef ADC_InitStruct = {0};
  LL_ADC_REG_InitTypeDef ADC_REG_InitStruct = {0};

  LL_GPIO_InitTypeDef GPIO_InitStruct = {0};

  /* Peripheral clock enable */
  LL_APB2_GRP1_EnableClock(LL_APB2_GRP1_PERIPH_ADC3);

  LL_AHB1_GRP1_EnableClock(LL_AHB1_GRP1_PERIPH_GPIOF);
  /**ADC3 GPIO Configuration
  PF10   ------> ADC3_IN8
  PF9   ------> ADC3_IN7
  PF8   ------> ADC3_IN6
  */
  GPIO_InitStruct.Pin = LL_GPIO_PIN_10;
  GPIO_InitStruct.Mode = LL_GPIO_MODE_ANALOG;
  GPIO_InitStruct.Pull = LL_GPIO_PULL_NO;
  LL_GPIO_Init(GPIOF, &GPIO_InitStruct);

  GPIO_InitStruct.Pin = LL_GPIO_PIN_9;
  GPIO_InitStruct.Mode = LL_GPIO_MODE_ANALOG;
  GPIO_InitStruct.Pull = LL_GPIO_PULL_NO;
  LL_GPIO_Init(GPIOF, &GPIO_InitStruct);

  GPIO_InitStruct.Pin = LL_GPIO_PIN_8;
  GPIO_InitStruct.Mode = LL_GPIO_MODE_ANALOG;
  GPIO_InitStruct.Pull = LL_GPIO_PULL_NO;
  LL_GPIO_Init(GPIOF, &GPIO_InitStruct);

  /** Common config
  */
  ADC_InitStruct.Resolution = LL_ADC_RESOLUTION_12B;
  ADC_InitStruct.DataAlignment = LL_ADC_DATA_ALIGN_RIGHT;
  ADC_InitStruct.SequencersScanMode = LL_ADC_SEQ_SCAN_DISABLE;
  LL_ADC_Init(ADC3, &ADC_InitStruct);
  ADC_REG_InitStruct.TriggerSource = LL_ADC_REG_TRIG_SOFTWARE;
  ADC_REG_InitStruct.SequencerLength = LL_ADC_REG_SEQ_SCAN_DISABLE;
  ADC_REG_InitStruct.SequencerDiscont = LL_ADC_REG_SEQ_DISCONT_DISABLE;
  ADC_REG_InitStruct.ContinuousMode = LL_ADC_REG_CONV_SINGLE;
  ADC_REG_InitStruct.DMATransfer = LL_ADC_REG_DMA_TRANSFER_NONE;
  LL_ADC_REG_Init(ADC3, &ADC_REG_InitStruct);
  LL_ADC_REG_SetFlagEndOfConversion(ADC3, LL_ADC_REG_FLAG_EOC_UNITARY_CONV);
  /** Configure Regular Channel
  */
  LL_ADC_REG_SetSequencerRanks(ADC3, LL_ADC_REG_RANK_1, LL_ADC_CHANNEL_6);
  LL_ADC_SetChannelSamplingTime(ADC3, LL_ADC_CHANNEL_6, LL_ADC_SAMPLINGTIME_3CYCLES);

}

static void MX_CRC_Init(void)
{

  hcrc.Instance = CRC;
  hcrc.Init.DefaultPolynomialUse = DEFAULT_POLYNOMIAL_ENABLE;
  hcrc.Init.DefaultInitValueUse = DEFAULT_INIT_VALUE_ENABLE;
  hcrc.Init.InputDataInversionMode = CRC_INPUTDATA_INVERSION_NONE;
  hcrc.Init.OutputDataInversionMode = CRC_OUTPUTDATA_INVERSION_DISABLE;
  hcrc.InputDataFormat = CRC_INPUTDATA_FORMAT_BYTES;
  if (HAL_CRC_Init(&hcrc) != HAL_OK)
  {
    Error_Handler();
  }

}

static void MX_DMA2D_Init(void)
{

  hdma2d.Instance = DMA2D;
  hdma2d.Init.Mode = DMA2D_R2M;
  hdma2d.Init.ColorMode = DMA2D_OUTPUT_ARGB8888;
  hdma2d.Init.OutputOffset = 0;
  if (HAL_DMA2D_Init(&hdma2d) != HAL_OK)
  {
    Error_Handler();
  }

}

static void MX_DSIHOST_DSI_Init(void)
{

  DSI_PLLInitTypeDef PLLInit = {0};
  DSI_HOST_TimeoutTypeDef HostTimeouts = {0};
  DSI_PHY_TimerTypeDef PhyTimings = {0};
  DSI_LPCmdTypeDef LPCmd = {0};
  DSI_CmdCfgTypeDef CmdCfg = {0};

  hdsi.Instance = DSI;
  hdsi.Init.AutomaticClockLaneControl = DSI_AUTO_CLK_LANE_CTRL_DISABLE;
  hdsi.Init.TXEscapeCkdiv = 4;
  hdsi.Init.NumberOfLanes = DSI_TWO_DATA_LANES;
  PLLInit.PLLNDIV = 20;
  PLLInit.PLLIDF = DSI_PLL_IN_DIV1;
  PLLInit.PLLODF = DSI_PLL_OUT_DIV1;
  if (HAL_DSI_Init(&hdsi, &PLLInit) != HAL_OK)
  {
    Error_Handler();
  }
  HostTimeouts.TimeoutCkdiv = 1;
  HostTimeouts.HighSpeedTransmissionTimeout = 0;
  HostTimeouts.LowPowerReceptionTimeout = 0;
  HostTimeouts.HighSpeedReadTimeout = 0;
  HostTimeouts.LowPowerReadTimeout = 0;
  HostTimeouts.HighSpeedWriteTimeout = 0;
  HostTimeouts.HighSpeedWritePrespMode = DSI_HS_PM_DISABLE;
  HostTimeouts.LowPowerWriteTimeout = 0;
  HostTimeouts.BTATimeout = 0;
  if (HAL_DSI_ConfigHostTimeouts(&hdsi, &HostTimeouts) != HAL_OK)
  {
    Error_Handler();
  }
  PhyTimings.ClockLaneHS2LPTime = 28;
  PhyTimings.ClockLaneLP2HSTime = 33;
  PhyTimings.DataLaneHS2LPTime = 15;
  PhyTimings.DataLaneLP2HSTime = 25;
  PhyTimings.DataLaneMaxReadTime = 0;
  PhyTimings.StopWaitTime = 10;
  if (HAL_DSI_ConfigPhyTimer(&hdsi, &PhyTimings) != HAL_OK)
  {
    Error_Handler();
  }
  if (HAL_DSI_ConfigFlowControl(&hdsi, DSI_FLOW_CONTROL_BTA) != HAL_OK)
  {
    Error_Handler();
  }
  if (HAL_DSI_SetLowPowerRXFilter(&hdsi, 10000) != HAL_OK)
  {
    Error_Handler();
  }
  if (HAL_DSI_ConfigErrorMonitor(&hdsi, HAL_DSI_ERROR_NONE) != HAL_OK)
  {
    Error_Handler();
  }
  LPCmd.LPGenShortWriteNoP = DSI_LP_GSW0P_ENABLE;
  LPCmd.LPGenShortWriteOneP = DSI_LP_GSW1P_ENABLE;
  LPCmd.LPGenShortWriteTwoP = DSI_LP_GSW2P_ENABLE;
  LPCmd.LPGenShortReadNoP = DSI_LP_GSR0P_ENABLE;
  LPCmd.LPGenShortReadOneP = DSI_LP_GSR1P_ENABLE;
  LPCmd.LPGenShortReadTwoP = DSI_LP_GSR2P_ENABLE;
  LPCmd.LPGenLongWrite = DSI_LP_GLW_ENABLE;
  LPCmd.LPDcsShortWriteNoP = DSI_LP_DSW0P_ENABLE;
  LPCmd.LPDcsShortWriteOneP = DSI_LP_DSW1P_ENABLE;
  LPCmd.LPDcsShortReadNoP = DSI_LP_DSR0P_ENABLE;
  LPCmd.LPDcsLongWrite = DSI_LP_DLW_ENABLE;
  LPCmd.LPMaxReadPacket = DSI_LP_MRDP_ENABLE;
  LPCmd.AcknowledgeRequest = DSI_ACKNOWLEDGE_DISABLE;
  if (HAL_DSI_ConfigCommand(&hdsi, &LPCmd) != HAL_OK)
  {
    Error_Handler();
  }
  CmdCfg.VirtualChannelID = 0;
  CmdCfg.ColorCoding = DSI_RGB888;
  CmdCfg.CommandSize = 400;
  CmdCfg.TearingEffectSource = DSI_TE_EXTERNAL;
  CmdCfg.TearingEffectPolarity = DSI_TE_RISING_EDGE;
  CmdCfg.HSPolarity = DSI_HSYNC_ACTIVE_LOW;
  CmdCfg.VSPolarity = DSI_VSYNC_ACTIVE_LOW;
  CmdCfg.DEPolarity = DSI_DATA_ENABLE_ACTIVE_HIGH;
  CmdCfg.VSyncPol = DSI_VSYNC_FALLING;
  CmdCfg.AutomaticRefresh = DSI_AR_ENABLE;
  CmdCfg.TEAcknowledgeRequest = DSI_TE_ACKNOWLEDGE_ENABLE;
  if (HAL_DSI_ConfigAdaptedCommandMode(&hdsi, &CmdCfg) != HAL_OK)
  {
    Error_Handler();
  }
  if (HAL_DSI_SetGenericVCID(&hdsi, 0) != HAL_OK)
  {
    Error_Handler();
  }

}

static void MX_HDMI_CEC_Init(void)
{

  hcec.Instance = CEC;
  hcec.Init.SignalFreeTime = CEC_DEFAULT_SFT;
  hcec.Init.Tolerance = CEC_STANDARD_TOLERANCE;
  hcec.Init.BRERxStop = CEC_RX_STOP_ON_BRE;
  hcec.Init.BREErrorBitGen = CEC_BRE_ERRORBIT_NO_GENERATION;
  hcec.Init.LBPEErrorBitGen = CEC_LBPE_ERRORBIT_NO_GENERATION;
  hcec.Init.BroadcastMsgNoErrorBitGen = CEC_BROADCASTERROR_ERRORBIT_GENERATION;
  hcec.Init.SignalFreeTimeOption = CEC_SFT_START_ON_TXSOM;
  hcec.Init.ListenMode = CEC_FULL_LISTENING_MODE;
  hcec.Init.OwnAddress = CEC_OWN_ADDRESS_NONE;
  hcec.Init.RxBuffer = cec_receive_buffer;
  if (HAL_CEC_Init(&hcec) != HAL_OK)
  {
    Error_Handler();
  }

}

static void MX_I2C1_Init(void)
{

  hi2c1.Instance = I2C1;
  hi2c1.Init.Timing = 0x00C0EAFF;
  hi2c1.Init.OwnAddress1 = 0;
  hi2c1.Init.AddressingMode = I2C_ADDRESSINGMODE_7BIT;
  hi2c1.Init.DualAddressMode = I2C_DUALADDRESS_DISABLE;
  hi2c1.Init.OwnAddress2 = 0;
  hi2c1.Init.OwnAddress2Masks = I2C_OA2_NOMASK;
  hi2c1.Init.GeneralCallMode = I2C_GENERALCALL_DISABLE;
  hi2c1.Init.NoStretchMode = I2C_NOSTRETCH_DISABLE;
  if (HAL_I2C_Init(&hi2c1) != HAL_OK)
  {
    Error_Handler();
  }
  /** Configure Analogue filter
  */
  if (HAL_I2CEx_ConfigAnalogFilter(&hi2c1, I2C_ANALOGFILTER_ENABLE) != HAL_OK)
  {
    Error_Handler();
  }
  /** Configure Digital filter
  */
  if (HAL_I2CEx_ConfigDigitalFilter(&hi2c1, 0) != HAL_OK)
  {
    Error_Handler();
  }

}

static void MX_I2C4_Init(void)
{

  hi2c4.Instance = I2C4;
  hi2c4.Init.Timing = 0x00C0EAFF;
  hi2c4.Init.OwnAddress1 = 0;
  hi2c4.Init.AddressingMode = I2C_ADDRESSINGMODE_7BIT;
  hi2c4.Init.DualAddressMode = I2C_DUALADDRESS_DISABLE;
  hi2c4.Init.OwnAddress2 = 0;
  hi2c4.Init.OwnAddress2Masks = I2C_OA2_NOMASK;
  hi2c4.Init.GeneralCallMode = I2C_GENERALCALL_DISABLE;
  hi2c4.Init.NoStretchMode = I2C_NOSTRETCH_DISABLE;
  if (HAL_I2C_Init(&hi2c4) != HAL_OK)
  {
    Error_Handler();
  }
  /** Configure Analogue filter
  */
  if (HAL_I2CEx_ConfigAnalogFilter(&hi2c4, I2C_ANALOGFILTER_ENABLE) != HAL_OK)
  {
    Error_Handler();
  }
  /** Configure Digital filter
  */
  if (HAL_I2CEx_ConfigDigitalFilter(&hi2c4, 0) != HAL_OK)
  {
    Error_Handler();
  }

}

static void MX_LTDC_Init(void)
{

  LTDC_LayerCfgTypeDef pLayerCfg = {0};

  hltdc.Instance = LTDC;
  hltdc.Init.HSPolarity = LTDC_HSPOLARITY_AL;
  hltdc.Init.VSPolarity = LTDC_VSPOLARITY_AL;
  hltdc.Init.DEPolarity = LTDC_DEPOLARITY_AL;
  hltdc.Init.PCPolarity = LTDC_PCPOLARITY_IPC;
  hltdc.Init.HorizontalSync = 0;
  hltdc.Init.VerticalSync = 0;
  hltdc.Init.AccumulatedHBP = 1;
  hltdc.Init.AccumulatedVBP = 1;
  hltdc.Init.AccumulatedActiveW = 201;
  hltdc.Init.AccumulatedActiveH = 481;
  hltdc.Init.TotalWidth = 202;
  hltdc.Init.TotalHeigh = 482;
  hltdc.Init.Backcolor.Blue = 0;
  hltdc.Init.Backcolor.Green = 0;
  hltdc.Init.Backcolor.Red = 0;
  if (HAL_LTDC_Init(&hltdc) != HAL_OK)
  {
    Error_Handler();
  }
  pLayerCfg.WindowX0 = 0;
  pLayerCfg.WindowX1 = 200;
  pLayerCfg.WindowY0 = 0;
  pLayerCfg.WindowY1 = 480;
  pLayerCfg.PixelFormat = LTDC_PIXEL_FORMAT_RGB565;
  pLayerCfg.Alpha = 255;
  pLayerCfg.Alpha0 = 0;
  pLayerCfg.BlendingFactor1 = LTDC_BLENDING_FACTOR1_PAxCA;
  pLayerCfg.BlendingFactor2 = LTDC_BLENDING_FACTOR2_PAxCA;
  pLayerCfg.FBStartAdress = 0xC0000000;
  pLayerCfg.ImageWidth = 200;
  pLayerCfg.ImageHeight = 480;
  pLayerCfg.Backcolor.Blue = 0;
  pLayerCfg.Backcolor.Green = 0;
  pLayerCfg.Backcolor.Red = 0;
  if (HAL_LTDC_ConfigLayer(&hltdc, &pLayerCfg, 0) != HAL_OK)
  {
    Error_Handler();
  }

}

static void MX_RTC_Init(void)
{

  RTC_TimeTypeDef sTime = {0};
  RTC_DateTypeDef sDate = {0};
  RTC_AlarmTypeDef sAlarm = {0};

  /** Initialize RTC Only
  */
  hrtc.Instance = RTC;
  hrtc.Init.HourFormat = RTC_HOURFORMAT_24;
  hrtc.Init.AsynchPrediv = 127;
  hrtc.Init.SynchPrediv = 255;
  hrtc.Init.OutPut = RTC_OUTPUT_DISABLE;
  hrtc.Init.OutPutPolarity = RTC_OUTPUT_POLARITY_HIGH;
  hrtc.Init.OutPutType = RTC_OUTPUT_TYPE_OPENDRAIN;
  if (HAL_RTC_Init(&hrtc) != HAL_OK)
  {
    Error_Handler();
  }

  /** Initialize RTC and set the Time and Date
  */
  sTime.Hours = 0x0;
  sTime.Minutes = 0x0;
  sTime.Seconds = 0x0;
  sTime.DayLightSaving = RTC_DAYLIGHTSAVING_NONE;
  sTime.StoreOperation = RTC_STOREOPERATION_RESET;
  if (HAL_RTC_SetTime(&hrtc, &sTime, RTC_FORMAT_BCD) != HAL_OK)
  {
    Error_Handler();
  }
  sDate.WeekDay = RTC_WEEKDAY_MONDAY;
  sDate.Month = RTC_MONTH_JANUARY;
  sDate.Date = 0x1;
  sDate.Year = 0x0;
  if (HAL_RTC_SetDate(&hrtc, &sDate, RTC_FORMAT_BCD) != HAL_OK)
  {
    Error_Handler();
  }
  /** Enable the Alarm B
  */
  sAlarm.AlarmTime.Hours = 0x0;
  sAlarm.AlarmTime.Minutes = 0x0;
  sAlarm.AlarmTime.Seconds = 0x0;
  sAlarm.AlarmTime.SubSeconds = 0x0;
  sAlarm.AlarmTime.DayLightSaving = RTC_DAYLIGHTSAVING_NONE;
  sAlarm.AlarmTime.StoreOperation = RTC_STOREOPERATION_RESET;
  sAlarm.AlarmMask = RTC_ALARMMASK_NONE;
  sAlarm.AlarmSubSecondMask = RTC_ALARMSUBSECONDMASK_ALL;
  sAlarm.AlarmDateWeekDaySel = RTC_ALARMDATEWEEKDAYSEL_DATE;
  sAlarm.AlarmDateWeekDay = 0x1;
  sAlarm.Alarm = RTC_ALARM_B;
  if (HAL_RTC_SetAlarm(&hrtc, &sAlarm, RTC_FORMAT_BCD) != HAL_OK)
  {
    Error_Handler();
  }

}

static void MX_SAI1_Init(void)
{

  hsai_BlockA1.Instance = SAI1_Block_A;
  hsai_BlockA1.Init.Protocol = SAI_FREE_PROTOCOL;
  hsai_BlockA1.Init.AudioMode = SAI_MODEMASTER_TX;
  hsai_BlockA1.Init.DataSize = SAI_DATASIZE_8;
  hsai_BlockA1.Init.FirstBit = SAI_FIRSTBIT_MSB;
  hsai_BlockA1.Init.ClockStrobing = SAI_CLOCKSTROBING_FALLINGEDGE;
  hsai_BlockA1.Init.Synchro = SAI_ASYNCHRONOUS;
  hsai_BlockA1.Init.OutputDrive = SAI_OUTPUTDRIVE_DISABLE;
  hsai_BlockA1.Init.NoDivider = SAI_MASTERDIVIDER_ENABLE;
  hsai_BlockA1.Init.FIFOThreshold = SAI_FIFOTHRESHOLD_EMPTY;
  hsai_BlockA1.Init.AudioFrequency = SAI_AUDIO_FREQUENCY_192K;
  hsai_BlockA1.Init.SynchroExt = SAI_SYNCEXT_DISABLE;
  hsai_BlockA1.Init.MonoStereoMode = SAI_STEREOMODE;
  hsai_BlockA1.Init.CompandingMode = SAI_NOCOMPANDING;
  hsai_BlockA1.Init.TriState = SAI_OUTPUT_NOTRELEASED;
  hsai_BlockA1.FrameInit.FrameLength = 8;
  hsai_BlockA1.FrameInit.ActiveFrameLength = 1;
  hsai_BlockA1.FrameInit.FSDefinition = SAI_FS_STARTFRAME;
  hsai_BlockA1.FrameInit.FSPolarity = SAI_FS_ACTIVE_LOW;
  hsai_BlockA1.FrameInit.FSOffset = SAI_FS_FIRSTBIT;
  hsai_BlockA1.SlotInit.FirstBitOffset = 0;
  hsai_BlockA1.SlotInit.SlotSize = SAI_SLOTSIZE_DATASIZE;
  hsai_BlockA1.SlotInit.SlotNumber = 1;
  hsai_BlockA1.SlotInit.SlotActive = 0x00000000;
  if (HAL_SAI_Init(&hsai_BlockA1) != HAL_OK)
  {
    Error_Handler();
  }
  hsai_BlockB1.Instance = SAI1_Block_B;
  hsai_BlockB1.Init.Protocol = SAI_FREE_PROTOCOL;
  hsai_BlockB1.Init.AudioMode = SAI_MODESLAVE_RX;
  hsai_BlockB1.Init.DataSize = SAI_DATASIZE_8;
  hsai_BlockB1.Init.FirstBit = SAI_FIRSTBIT_MSB;
  hsai_BlockB1.Init.ClockStrobing = SAI_CLOCKSTROBING_FALLINGEDGE;
  hsai_BlockB1.Init.Synchro = SAI_SYNCHRONOUS;
  hsai_BlockB1.Init.OutputDrive = SAI_OUTPUTDRIVE_DISABLE;
  hsai_BlockB1.Init.FIFOThreshold = SAI_FIFOTHRESHOLD_EMPTY;
  hsai_BlockB1.Init.SynchroExt = SAI_SYNCEXT_DISABLE;
  hsai_BlockB1.Init.MonoStereoMode = SAI_STEREOMODE;
  hsai_BlockB1.Init.CompandingMode = SAI_NOCOMPANDING;
  hsai_BlockB1.Init.TriState = SAI_OUTPUT_NOTRELEASED;
  hsai_BlockB1.FrameInit.FrameLength = 8;
  hsai_BlockB1.FrameInit.ActiveFrameLength = 1;
  hsai_BlockB1.FrameInit.FSDefinition = SAI_FS_STARTFRAME;
  hsai_BlockB1.FrameInit.FSPolarity = SAI_FS_ACTIVE_LOW;
  hsai_BlockB1.FrameInit.FSOffset = SAI_FS_FIRSTBIT;
  hsai_BlockB1.SlotInit.FirstBitOffset = 0;
  hsai_BlockB1.SlotInit.SlotSize = SAI_SLOTSIZE_DATASIZE;
  hsai_BlockB1.SlotInit.SlotNumber = 1;
  hsai_BlockB1.SlotInit.SlotActive = 0x00000000;
  if (HAL_SAI_Init(&hsai_BlockB1) != HAL_OK)
  {
    Error_Handler();
  }

}

static void MX_SAI2_Init(void)
{

  hsai_BlockA2.Instance = SAI2_Block_A;
  hsai_BlockA2.Init.Protocol = SAI_SPDIF_PROTOCOL;
  hsai_BlockA2.Init.AudioMode = SAI_MODEMASTER_TX;
  hsai_BlockA2.Init.Synchro = SAI_ASYNCHRONOUS;
  hsai_BlockA2.Init.OutputDrive = SAI_OUTPUTDRIVE_DISABLE;
  hsai_BlockA2.Init.FIFOThreshold = SAI_FIFOTHRESHOLD_EMPTY;
  hsai_BlockA2.Init.AudioFrequency = SAI_AUDIO_FREQUENCY_48K;
  hsai_BlockA2.Init.MonoStereoMode = SAI_STEREOMODE;
  hsai_BlockA2.Init.CompandingMode = SAI_NOCOMPANDING;
  if (HAL_SAI_Init(&hsai_BlockA2) != HAL_OK)
  {
    Error_Handler();
  }

}

static void MX_SPDIFRX_Init(void)
{

  hspdif.Instance = SPDIFRX;
  hspdif.Init.InputSelection = SPDIFRX_INPUT_IN1;
  hspdif.Init.Retries = SPDIFRX_MAXRETRIES_NONE;
  hspdif.Init.WaitForActivity = SPDIFRX_WAITFORACTIVITY_OFF;
  hspdif.Init.ChannelSelection = SPDIFRX_CHANNEL_A;
  hspdif.Init.DataFormat = SPDIFRX_DATAFORMAT_LSB;
  hspdif.Init.StereoMode = SPDIFRX_STEREOMODE_DISABLE;
  hspdif.Init.PreambleTypeMask = SPDIFRX_PREAMBLETYPEMASK_OFF;
  hspdif.Init.ChannelStatusMask = SPDIFRX_CHANNELSTATUS_OFF;
  hspdif.Init.ValidityBitMask = SPDIFRX_VALIDITYMASK_OFF;
  hspdif.Init.ParityErrorMask = SPDIFRX_PARITYERRORMASK_OFF;
  if (HAL_SPDIFRX_Init(&hspdif) != HAL_OK)
  {
    Error_Handler();
  }

}

static void MX_TIM1_Init(void)
{

  TIM_ClockConfigTypeDef sClockSourceConfig = {0};
  TIM_MasterConfigTypeDef sMasterConfig = {0};

  htim1.Instance = TIM1;
  htim1.Init.Prescaler = 0;
  htim1.Init.CounterMode = TIM_COUNTERMODE_UP;
  htim1.Init.Period = 65535;
  htim1.Init.ClockDivision = TIM_CLOCKDIVISION_DIV1;
  htim1.Init.RepetitionCounter = 0;
  htim1.Init.AutoReloadPreload = TIM_AUTORELOAD_PRELOAD_DISABLE;
  if (HAL_TIM_Base_Init(&htim1) != HAL_OK)
  {
    Error_Handler();
  }
  sClockSourceConfig.ClockSource = TIM_CLOCKSOURCE_INTERNAL;
  if (HAL_TIM_ConfigClockSource(&htim1, &sClockSourceConfig) != HAL_OK)
  {
    Error_Handler();
  }
  sMasterConfig.MasterOutputTrigger = TIM_TRGO_RESET;
  sMasterConfig.MasterOutputTrigger2 = TIM_TRGO2_RESET;
  sMasterConfig.MasterSlaveMode = TIM_MASTERSLAVEMODE_DISABLE;
  if (HAL_TIMEx_MasterConfigSynchronization(&htim1, &sMasterConfig) != HAL_OK)
  {
    Error_Handler();
  }

}

static void MX_TIM3_Init(void)
{

  TIM_MasterConfigTypeDef sMasterConfig = {0};
  TIM_OC_InitTypeDef sConfigOC = {0};

  htim3.Instance = TIM3;
  htim3.Init.Prescaler = 0;
  htim3.Init.CounterMode = TIM_COUNTERMODE_UP;
  htim3.Init.Period = 65535;
  htim3.Init.ClockDivision = TIM_CLOCKDIVISION_DIV1;
  htim3.Init.AutoReloadPreload = TIM_AUTORELOAD_PRELOAD_DISABLE;
  if (HAL_TIM_PWM_Init(&htim3) != HAL_OK)
  {
    Error_Handler();
  }
  sMasterConfig.MasterOutputTrigger = TIM_TRGO_RESET;
  sMasterConfig.MasterSlaveMode = TIM_MASTERSLAVEMODE_DISABLE;
  if (HAL_TIMEx_MasterConfigSynchronization(&htim3, &sMasterConfig) != HAL_OK)
  {
    Error_Handler();
  }
  sConfigOC.OCMode = TIM_OCMODE_PWM1;
  sConfigOC.Pulse = 0;
  sConfigOC.OCPolarity = TIM_OCPOLARITY_HIGH;
  sConfigOC.OCFastMode = TIM_OCFAST_DISABLE;
  if (HAL_TIM_PWM_ConfigChannel(&htim3, &sConfigOC, TIM_CHANNEL_3) != HAL_OK)
  {
    Error_Handler();
  }
  HAL_TIM_MspPostInit(&htim3);

}

static void MX_TIM10_Init(void)
{

  TIM_OC_InitTypeDef sConfigOC = {0};

  htim10.Instance = TIM10;
  htim10.Init.Prescaler = 0;
  htim10.Init.CounterMode = TIM_COUNTERMODE_UP;
  htim10.Init.Period = 65535;
  htim10.Init.ClockDivision = TIM_CLOCKDIVISION_DIV1;
  htim10.Init.AutoReloadPreload = TIM_AUTORELOAD_PRELOAD_DISABLE;
  if (HAL_TIM_Base_Init(&htim10) != HAL_OK)
  {
    Error_Handler();
  }
  if (HAL_TIM_PWM_Init(&htim10) != HAL_OK)
  {
    Error_Handler();
  }
  sConfigOC.OCMode = TIM_OCMODE_PWM1;
  sConfigOC.Pulse = 0;
  sConfigOC.OCPolarity = TIM_OCPOLARITY_HIGH;
  sConfigOC.OCFastMode = TIM_OCFAST_DISABLE;
  if (HAL_TIM_PWM_ConfigChannel(&htim10, &sConfigOC, TIM_CHANNEL_1) != HAL_OK)
  {
    Error_Handler();
  }
  HAL_TIM_MspPostInit(&htim10);

}

static void MX_TIM11_Init(void)
{

  TIM_OC_InitTypeDef sConfigOC = {0};

  htim11.Instance = TIM11;
  htim11.Init.Prescaler = 0;
  htim11.Init.CounterMode = TIM_COUNTERMODE_UP;
  htim11.Init.Period = 65535;
  htim11.Init.ClockDivision = TIM_CLOCKDIVISION_DIV1;
  htim11.Init.AutoReloadPreload = TIM_AUTORELOAD_PRELOAD_DISABLE;
  if (HAL_TIM_Base_Init(&htim11) != HAL_OK)
  {
    Error_Handler();
  }
  if (HAL_TIM_PWM_Init(&htim11) != HAL_OK)
  {
    Error_Handler();
  }
  sConfigOC.OCMode = TIM_OCMODE_PWM1;
  sConfigOC.Pulse = 0;
  sConfigOC.OCPolarity = TIM_OCPOLARITY_HIGH;
  sConfigOC.OCFastMode = TIM_OCFAST_DISABLE;
  if (HAL_TIM_PWM_ConfigChannel(&htim11, &sConfigOC, TIM_CHANNEL_1) != HAL_OK)
  {
    Error_Handler();
  }
  HAL_TIM_MspPostInit(&htim11);

}

static void MX_TIM12_Init(void)
{

  TIM_OC_InitTypeDef sConfigOC = {0};

  htim12.Instance = TIM12;
  htim12.Init.Prescaler = 0;
  htim12.Init.CounterMode = TIM_COUNTERMODE_UP;
  htim12.Init.Period = 65535;
  htim12.Init.ClockDivision = TIM_CLOCKDIVISION_DIV1;
  htim12.Init.AutoReloadPreload = TIM_AUTORELOAD_PRELOAD_DISABLE;
  if (HAL_TIM_PWM_Init(&htim12) != HAL_OK)
  {
    Error_Handler();
  }
  sConfigOC.OCMode = TIM_OCMODE_PWM1;
  sConfigOC.Pulse = 0;
  sConfigOC.OCPolarity = TIM_OCPOLARITY_HIGH;
  sConfigOC.OCFastMode = TIM_OCFAST_DISABLE;
  if (HAL_TIM_PWM_ConfigChannel(&htim12, &sConfigOC, TIM_CHANNEL_1) != HAL_OK)
  {
    Error_Handler();
  }
  HAL_TIM_MspPostInit(&htim12);

}

static void MX_UART5_Init(void)
{

  huart5.Instance = UART5;
  huart5.Init.BaudRate = 115200;
  huart5.Init.WordLength = UART_WORDLENGTH_8B;
  huart5.Init.StopBits = UART_STOPBITS_1;
  huart5.Init.Parity = UART_PARITY_NONE;
  huart5.Init.Mode = UART_MODE_TX_RX;
  huart5.Init.HwFlowCtl = UART_HWCONTROL_NONE;
  huart5.Init.OverSampling = UART_OVERSAMPLING_16;
  huart5.Init.OneBitSampling = UART_ONE_BIT_SAMPLE_DISABLE;
  huart5.AdvancedInit.AdvFeatureInit = UART_ADVFEATURE_NO_INIT;
  if (HAL_UART_Init(&huart5) != HAL_OK)
  {
    Error_Handler();
  }

}

static void MX_USART1_UART_Init(void)
{

  huart1.Instance = USART1;
  huart1.Init.BaudRate = 115200;
  huart1.Init.WordLength = UART_WORDLENGTH_8B;
  huart1.Init.StopBits = UART_STOPBITS_1;
  huart1.Init.Parity = UART_PARITY_NONE;
  huart1.Init.Mode = UART_MODE_TX_RX;
  huart1.Init.HwFlowCtl = UART_HWCONTROL_NONE;
  huart1.Init.OverSampling = UART_OVERSAMPLING_16;
  huart1.Init.OneBitSampling = UART_ONE_BIT_SAMPLE_DISABLE;
  huart1.AdvancedInit.AdvFeatureInit = UART_ADVFEATURE_NO_INIT;
  if (HAL_UART_Init(&huart1) != HAL_OK)
  {
    Error_Handler();
  }

}

static void MX_USART6_UART_Init(void)
{

  huart6.Instance = USART6;
  huart6.Init.BaudRate = 115200;
  huart6.Init.WordLength = UART_WORDLENGTH_8B;
  huart6.Init.StopBits = UART_STOPBITS_1;
  huart6.Init.Parity = UART_PARITY_NONE;
  huart6.Init.Mode = UART_MODE_TX_RX;
  huart6.Init.HwFlowCtl = UART_HWCONTROL_NONE;
  huart6.Init.OverSampling = UART_OVERSAMPLING_16;
  huart6.Init.OneBitSampling = UART_ONE_BIT_SAMPLE_DISABLE;
  huart6.AdvancedInit.AdvFeatureInit = UART_ADVFEATURE_NO_INIT;
  if (HAL_UART_Init(&huart6) != HAL_OK)
  {
    Error_Handler();
  }

}

/* FMC initialization function */
static void MX_FMC_Init(void)
{

  FMC_SDRAM_TimingTypeDef SdramTiming = {0};

  /** Perform the SDRAM1 memory initialization sequence
  */
  hsdram1.Instance = FMC_SDRAM_DEVICE;
  /* hsdram1.Init */
  hsdram1.Init.SDBank = FMC_SDRAM_BANK1;
  hsdram1.Init.ColumnBitsNumber = FMC_SDRAM_COLUMN_BITS_NUM_8;
  hsdram1.Init.RowBitsNumber = FMC_SDRAM_ROW_BITS_NUM_12;
  hsdram1.Init.MemoryDataWidth = FMC_SDRAM_MEM_BUS_WIDTH_32;
  hsdram1.Init.InternalBankNumber = FMC_SDRAM_INTERN_BANKS_NUM_4;
  hsdram1.Init.CASLatency = FMC_SDRAM_CAS_LATENCY_3;
  hsdram1.Init.WriteProtection = FMC_SDRAM_WRITE_PROTECTION_DISABLE;
  hsdram1.Init.SDClockPeriod = FMC_SDRAM_CLOCK_PERIOD_2;
  hsdram1.Init.ReadBurst = FMC_SDRAM_RBURST_ENABLE;
  hsdram1.Init.ReadPipeDelay = FMC_SDRAM_RPIPE_DELAY_0;
  /* SdramTiming */
  SdramTiming.LoadToActiveDelay = 2;
  SdramTiming.ExitSelfRefreshDelay = 7;
  SdramTiming.SelfRefreshTime = 4;
  SdramTiming.RowCycleDelay = 7;
  SdramTiming.WriteRecoveryTime = 3;
  SdramTiming.RPDelay = 2;
  SdramTiming.RCDDelay = 2;

  if (HAL_SDRAM_Init(&hsdram1, &SdramTiming) != HAL_OK)
  {
    Error_Handler( );
  }

}

static void MX_GPIO_Init(void)
{
  GPIO_InitTypeDef GPIO_InitStruct = {0};

  /* GPIO Ports Clock Enable */
  __HAL_RCC_GPIOE_CLK_ENABLE();
  __HAL_RCC_GPIOB_CLK_ENABLE();
  __HAL_RCC_GPIOC_CLK_ENABLE();
  __HAL_RCC_GPIOA_CLK_ENABLE();
  __HAL_RCC_GPIOG_CLK_ENABLE();
  __HAL_RCC_GPIOJ_CLK_ENABLE();
  __HAL_RCC_GPIOD_CLK_ENABLE();
  __HAL_RCC_GPIOI_CLK_ENABLE();
  __HAL_RCC_GPIOK_CLK_ENABLE();
  __HAL_RCC_GPIOF_CLK_ENABLE();
  __HAL_RCC_GPIOH_CLK_ENABLE();

  /*Configure GPIO pin Output Level */
  HAL_GPIO_WritePin(GPIOJ, GPIO_PIN_13|DSI_RESET_Pin|GPIO_PIN_5, GPIO_PIN_RESET);

  /*Configure GPIO pin Output Level */
  HAL_GPIO_WritePin(GPIOA, GPIO_PIN_12, GPIO_PIN_RESET);

  /*Configure GPIO pins : PJ13 DSI_RESET_Pin PJ5 */
  GPIO_InitStruct.Pin = GPIO_PIN_13|DSI_RESET_Pin|GPIO_PIN_5;
  GPIO_InitStruct.Mode = GPIO_MODE_OUTPUT_PP;
  GPIO_InitStruct.Pull = GPIO_NOPULL;
  GPIO_InitStruct.Speed = GPIO_SPEED_FREQ_LOW;
  HAL_GPIO_Init(GPIOJ, &GPIO_InitStruct);

  /*Configure GPIO pins : Audio_INT_Pin WIFI_RST_Pin ARD_D8_Pin ARD_D7_Pin
                           ARD_D4_Pin ARD_D2_Pin */
  GPIO_InitStruct.Pin = Audio_INT_Pin|WIFI_RST_Pin|ARD_D8_Pin|ARD_D7_Pin
                          |ARD_D4_Pin|ARD_D2_Pin;
  GPIO_InitStruct.Mode = GPIO_MODE_INPUT;
  GPIO_InitStruct.Pull = GPIO_NOPULL;
  HAL_GPIO_Init(GPIOJ, &GPIO_InitStruct);

  /*Configure GPIO pin : PA12 */
  GPIO_InitStruct.Pin = GPIO_PIN_12;
  GPIO_InitStruct.Mode = GPIO_MODE_OUTPUT_PP;
  GPIO_InitStruct.Pull = GPIO_NOPULL;
  GPIO_InitStruct.Speed = GPIO_SPEED_FREQ_LOW;
  HAL_GPIO_Init(GPIOA, &GPIO_InitStruct);

  /*Configure GPIO pins : NC4_Pin NC5_Pin uSD_Detect_Pin LCD_BL_CTRL_Pin */
  GPIO_InitStruct.Pin = NC4_Pin|NC5_Pin|uSD_Detect_Pin|LCD_BL_CTRL_Pin;
  GPIO_InitStruct.Mode = GPIO_MODE_INPUT;
  GPIO_InitStruct.Pull = GPIO_NOPULL;
  HAL_GPIO_Init(GPIOI, &GPIO_InitStruct);

  /*Configure GPIO pins : NC3_Pin NC2_Pin NC1_Pin NC8_Pin
                           NC7_Pin */
  GPIO_InitStruct.Pin = NC3_Pin|NC2_Pin|NC1_Pin|NC8_Pin
                          |NC7_Pin;
  GPIO_InitStruct.Mode = GPIO_MODE_INPUT;
  GPIO_InitStruct.Pull = GPIO_NOPULL;
  HAL_GPIO_Init(GPIOK, &GPIO_InitStruct);

  /*Configure GPIO pins : RMII_RXER_Pin OTG_FS_OverCurrent_Pin */
  GPIO_InitStruct.Pin = RMII_RXER_Pin|OTG_FS_OverCurrent_Pin;
  GPIO_InitStruct.Mode = GPIO_MODE_INPUT;
  GPIO_InitStruct.Pull = GPIO_NOPULL;
  HAL_GPIO_Init(GPIOD, &GPIO_InitStruct);

  /*Configure GPIO pin : CEC_CLK_Pin */
  GPIO_InitStruct.Pin = CEC_CLK_Pin;
  GPIO_InitStruct.Mode = GPIO_MODE_AF_PP;
  GPIO_InitStruct.Pull = GPIO_NOPULL;
  GPIO_InitStruct.Speed = GPIO_SPEED_FREQ_LOW;
  GPIO_InitStruct.Alternate = GPIO_AF0_MCO;
  HAL_GPIO_Init(CEC_CLK_GPIO_Port, &GPIO_InitStruct);

  /*Configure GPIO pin : LCD_INT_Pin */
  GPIO_InitStruct.Pin = LCD_INT_Pin;
  GPIO_InitStruct.Mode = GPIO_MODE_EVT_RISING;
  GPIO_InitStruct.Pull = GPIO_NOPULL;
  HAL_GPIO_Init(LCD_INT_GPIO_Port, &GPIO_InitStruct);

  /*Configure GPIO pins : EXT_SDA_Pin EXT_SCL_Pin */
  GPIO_InitStruct.Pin = EXT_SDA_Pin|EXT_SCL_Pin;
  GPIO_InitStruct.Mode = GPIO_MODE_INPUT;
  GPIO_InitStruct.Pull = GPIO_NOPULL;
  HAL_GPIO_Init(GPIOG, &GPIO_InitStruct);

  /*Configure GPIO pin : B_USER_Pin */
  GPIO_InitStruct.Pin = B_USER_Pin;
  GPIO_InitStruct.Mode = GPIO_MODE_IT_RISING;
  GPIO_InitStruct.Pull = GPIO_NOPULL;
  HAL_GPIO_Init(B_USER_GPIO_Port, &GPIO_InitStruct);

  /*Configure GPIO pin : PH7 */
  GPIO_InitStruct.Pin = GPIO_PIN_7;
  GPIO_InitStruct.Mode = GPIO_MODE_INPUT;
  GPIO_InitStruct.Pull = GPIO_NOPULL;
  HAL_GPIO_Init(GPIOH, &GPIO_InitStruct);

}

/* USER CODE BEGIN 4 */

/**
  * @brief  Fills buffer with user predefined data.
  * @param  pBuffer: pointer on the buffer to fill
  * @param  uwBufferLenght: size of the buffer to fill
  * @param  uwOffset: first value to fill on the buffer
  * @retval None
  */
static void Fill_Buffer(uint32_t *pBuffer, uint32_t uwBufferLenght, uint32_t uwOffset)
{
  uint32_t tmpIndex = 0;

  /* Put in global buffer different values */
  for (tmpIndex = 0; tmpIndex < uwBufferLenght; tmpIndex++ )
  {
    pBuffer[tmpIndex] = tmpIndex + uwOffset;
  }
}

/**
  * @brief  Display main demo messages
  * @param  None
  * @retval None
  */
static void Display_DemoDescription(void)
{
  char desc[50];

  /* Set LCD Foreground Layer  */
  BSP_LCD_SelectLayer(0);

  BSP_LCD_SetFont(&LCD_DEFAULT_FONT);

  /* Clear the LCD */
  BSP_LCD_SetBackColor(LCD_COLOR_WHITE);
  BSP_LCD_Clear(LCD_COLOR_WHITE);

  /* Set the LCD Text Color */
  BSP_LCD_SetTextColor(LCD_COLOR_DARKBLUE);

  /* Display LCD messages */
  BSP_LCD_DisplayStringAt(0, 10, (uint8_t *)"STM32F769I BSP", CENTER_MODE);
  BSP_LCD_DisplayStringAt(0, 35, (uint8_t *)"Drivers examples", CENTER_MODE);

  /* Draw Bitmap */
  BSP_LCD_DrawBitmap((BSP_LCD_GetXSize() - 80)/2, 65, (uint8_t *)stlogo);

  BSP_LCD_SetFont(&Font12);
  BSP_LCD_DisplayStringAt(0, BSP_LCD_GetYSize()- 20, (uint8_t *)"Copyright (c) STMicroelectronics 2016", CENTER_MODE);

  BSP_LCD_SetFont(&Font16);
  BSP_LCD_SetTextColor(LCD_COLOR_BLUE);
  BSP_LCD_FillRect(0, BSP_LCD_GetYSize()/2 + 15, BSP_LCD_GetXSize(), 60);
  BSP_LCD_SetTextColor(LCD_COLOR_WHITE);
  BSP_LCD_SetBackColor(LCD_COLOR_BLUE);
  BSP_LCD_DisplayStringAt(0, BSP_LCD_GetYSize() / 2 + 30, (uint8_t *)"Press User button to start :", CENTER_MODE);
//  sprintf(desc,"%s example", BSP_examples[DemoIndex].DemoName);
  BSP_LCD_DisplayStringAt(0, BSP_LCD_GetYSize()/2 + 45, (uint8_t *)desc, CENTER_MODE);
}

/**
  * @brief  Display LCD demo hint
  * @param  None
  * @retval None
  */
static void LCD_SetHint(void)
{
  /* Clear the LCD */
  BSP_LCD_Clear(LCD_COLOR_WHITE);

  /* Set LCD Demo description */
  BSP_LCD_SetTextColor(LCD_COLOR_BLUE);
  BSP_LCD_FillRect(0, 0, BSP_LCD_GetXSize(), 80);
  BSP_LCD_SetTextColor(LCD_COLOR_WHITE);
  BSP_LCD_SetBackColor(LCD_COLOR_BLUE);
  BSP_LCD_SetFont(&Font24);
  BSP_LCD_DisplayStringAt(0, 0, (uint8_t *)"LCD", CENTER_MODE);
  BSP_LCD_SetFont(&Font12);
  BSP_LCD_DisplayStringAt(0, 30, (uint8_t *)"This example shows the different", CENTER_MODE);
  BSP_LCD_DisplayStringAt(0, 45, (uint8_t *)"LCD Features, use User button to display", CENTER_MODE);
  BSP_LCD_DisplayStringAt(0, 60, (uint8_t *)"next page", CENTER_MODE);

   /* Set the LCD Text Color */
  BSP_LCD_SetTextColor(LCD_COLOR_BLUE);
  BSP_LCD_DrawRect(10, 90, BSP_LCD_GetXSize() - 20, BSP_LCD_GetYSize()- 100);
  BSP_LCD_DrawRect(11, 91, BSP_LCD_GetXSize() - 22, BSP_LCD_GetYSize()- 102);
 }

/**
  * @brief  Show LCD Features
  * @param  feature : feature index
  * @retval None
  */
static void LCD_Show_Feature(uint8_t feature)
{
  Point Points[]= {{20, 150}, {80, 150}, {80, 200}};
  Point Points2[3];

  Points2[0].X = BSP_LCD_GetXSize() - 80;
  Points2[0].Y = 150;
  Points2[1].X = BSP_LCD_GetXSize() - 20;
  Points2[1].Y = 150;
  Points2[2].X = BSP_LCD_GetXSize() - 20;
  Points2[2].Y = 200;

  BSP_LCD_SetBackColor(LCD_COLOR_WHITE);
  BSP_LCD_SetTextColor(LCD_COLOR_WHITE);
  BSP_LCD_FillRect(12, 92, BSP_LCD_GetXSize() - 24, BSP_LCD_GetYSize()- 104);
  BSP_LCD_SetTextColor(LCD_COLOR_BLACK);

  switch (feature)
  {
  case 0:
    /* Text Feature */

    BSP_LCD_DisplayStringAt(14, 100, (uint8_t *)"Left aligned Text", LEFT_MODE);
    BSP_LCD_DisplayStringAt(0, 115, (uint8_t *)"Center aligned Text", CENTER_MODE);
    BSP_LCD_DisplayStringAt(14, 130, (uint8_t*)"Right aligned Text", RIGHT_MODE);
    BSP_LCD_SetFont(&Font24);
    BSP_LCD_DisplayStringAt(14, 180, (uint8_t *)"Font24", LEFT_MODE);
    BSP_LCD_SetFont(&Font20);
    BSP_LCD_DisplayStringAt(BSP_LCD_GetXSize()/2 -20, 180, (uint8_t *)"Font20", LEFT_MODE);
    BSP_LCD_SetFont(&Font16);
    BSP_LCD_DisplayStringAt(BSP_LCD_GetXSize() - 80, 184, (uint8_t *)"Font16", LEFT_MODE);
    break;

  case 1:

    /* Draw misc. Shapes */
    BSP_LCD_SetTextColor(LCD_COLOR_BLACK);
    BSP_LCD_DrawRect(20, 100, 60 , 40);
    BSP_LCD_FillRect(100, 100, 60 , 40);

    BSP_LCD_SetTextColor(LCD_COLOR_GRAY);
    BSP_LCD_DrawCircle(BSP_LCD_GetXSize() - 120, 120, 20);
    BSP_LCD_FillCircle(BSP_LCD_GetXSize() - 40, 120, 20);

    BSP_LCD_SetTextColor(LCD_COLOR_GREEN);
    BSP_LCD_DrawPolygon(Points, 3);

    BSP_LCD_SetTextColor(LCD_COLOR_RED);
    BSP_LCD_DrawEllipse(130, 170, 30, 20);
    BSP_LCD_FillEllipse(200, 170, 30, 20);

    BSP_LCD_SetTextColor(LCD_COLOR_BLACK);
    BSP_LCD_DrawHLine(20, BSP_LCD_GetYSize() - 30, BSP_LCD_GetXSize() / 5);
    BSP_LCD_DrawLine (100, BSP_LCD_GetYSize() - 20, 230, BSP_LCD_GetYSize()- 50);
    BSP_LCD_DrawLine (100, BSP_LCD_GetYSize()- 50, 230, BSP_LCD_GetYSize()- 20);

    BSP_LCD_SetTextColor(LCD_COLOR_GREEN);
    BSP_LCD_FillPolygon(Points2, 3);
    break;

  case 2:
    /* Draw Bitmap */
    BSP_LCD_DrawBitmap(20, 100, (uint8_t *)stlogo);
    HAL_Delay(500);

    BSP_LCD_DrawBitmap(BSP_LCD_GetXSize()/2 - 40, 100, (uint8_t *)stlogo);
    HAL_Delay(500);

    BSP_LCD_DrawBitmap(BSP_LCD_GetXSize()-100, 100, (uint8_t *)stlogo);
    HAL_Delay(500);

    BSP_LCD_DrawBitmap(20, BSP_LCD_GetYSize()- 80, (uint8_t *)stlogo);
    HAL_Delay(500);

    BSP_LCD_DrawBitmap(BSP_LCD_GetXSize()/2 - 40, BSP_LCD_GetYSize()- 80, (uint8_t *)stlogo);
    HAL_Delay(500);

    BSP_LCD_DrawBitmap(BSP_LCD_GetXSize()-100, BSP_LCD_GetYSize()- 80, (uint8_t *)stlogo);
    HAL_Delay(500);
    break;
  }
}

/**
  * @brief  Touchscreen Demo1 : test touchscreen calibration and single touch in polling mode
  * @param  None
  * @retval None
  */
void Touchscreen_demo1(void)
{
  uint16_t x1, y1;
  uint8_t state = 0;
  uint8_t exitTsUseCase = 0;
  uint32_t ts_status = TS_OK;

  /* Reset touch data information */
//  BSP_TEST_APPLI_ASSERT(BSP_TS_ResetTouchData(&TS_State));

  /* Touchscreen initialization */
  ts_status = BSP_TS_Init(BSP_LCD_GetXSize(), BSP_LCD_GetYSize());

  if(ts_status == TS_OK)
  {
    /* Display touch screen demo description */
    Touchscreen_SetHint_Demo(TOUCHSCREEN_DEMO_1);
    Touchscreen_DrawBackground_Circles(state);

    while (exitTsUseCase == 0)
    {
      if (ts_status == TS_OK)
      {
        /* Check in polling mode in touch screen the touch status and coordinates */
        /* of touches if touch occurred                                           */
        ts_status = BSP_TS_GetState(&TS_State);
        if(TS_State.touchDetected)
        {
          /* One or dual touch have been detected          */
          /* Only take into account the first touch so far */

          /* Get X and Y position of the first touch post calibrated */
          x1 = TS_State.touchX[0];
          y1 = TS_State.touchY[0];

          if ((y1 > (CIRCLE_YPOS(1) - CIRCLE_RADIUS)) &&
              (y1 < (CIRCLE_YPOS(1) + CIRCLE_RADIUS)))
          {
            if ((x1 > (CIRCLE_XPOS(1) - CIRCLE_RADIUS)) &&
                (x1 < (CIRCLE_XPOS(1) + CIRCLE_RADIUS)))
            {
              if ((state & 1) == 0)
              {
                Touchscreen_DrawBackground_Circles(state);
                BSP_LCD_SetTextColor(LCD_COLOR_BLUE);
                BSP_LCD_FillCircle(CIRCLE_XPOS(1), CIRCLE_YPOS(1), CIRCLE_RADIUS);
                state = 1;
              }
            }
            if ((x1 > (CIRCLE_XPOS(2) - CIRCLE_RADIUS)) &&
                (x1 < (CIRCLE_XPOS(2) + CIRCLE_RADIUS)))
            {
              if ((state & 2) == 0)
              {
                Touchscreen_DrawBackground_Circles(state);
                BSP_LCD_SetTextColor(LCD_COLOR_RED);
                BSP_LCD_FillCircle(CIRCLE_XPOS(2), CIRCLE_YPOS(2), CIRCLE_RADIUS);
                state = 2;
              }
            }

            if ((x1 > (CIRCLE_XPOS(3) - CIRCLE_RADIUS)) &&
                (x1 < (CIRCLE_XPOS(3) + CIRCLE_RADIUS)))
            {
              if ((state & 4) == 0)
              {
                Touchscreen_DrawBackground_Circles(state);
                BSP_LCD_SetTextColor(LCD_COLOR_YELLOW);
                BSP_LCD_FillCircle(CIRCLE_XPOS(3), CIRCLE_YPOS(3), CIRCLE_RADIUS);
                state = 4;
              }
            }

            if ((x1 > (CIRCLE_XPOS(4) - CIRCLE_RADIUS)) &&
                (x1 < (CIRCLE_XPOS(4) + CIRCLE_RADIUS)))
            {
              if ((state & 8) == 0)
              {
                Touchscreen_DrawBackground_Circles(state);
                BSP_LCD_SetTextColor(LCD_COLOR_GREEN);
                BSP_LCD_FillCircle(CIRCLE_XPOS(4), CIRCLE_YPOS(3), CIRCLE_RADIUS);
                state = 8;
              }
            }
          }

        } /* of if(TS_State.TouchDetected) */

      } /* of if (ts_status == TS_OK) */

      /* Wait for a key button press to switch to next test case of BSP validation application */
      /* Otherwise stay in the test */
      exitTsUseCase = CheckForUserInput();

      HAL_Delay(20);

    } /* of while (exitTsUseCase == 0) */

  } /* of if(status == TS_OK) */
}

/**
  * @brief  Display TS Demo Hint for all touchscreen demos depending on passed
  *         demoIndex in parameter.
  * @param  demoIndex : parameter of type @ref TouchScreenDemoTypeDef
  * @retval None
  */
static void Touchscreen_SetHint_Demo(TouchScreenDemoTypeDef demoIndex)
{
  if(demoIndex <= TOUCHSCREEN_DEMO_MAX)
  {
    /* Clear the LCD */
    BSP_LCD_Clear(LCD_COLOR_WHITE);

    /* Set Touchscreen Demo1 description */
    BSP_LCD_SetTextColor(LCD_COLOR_BLUE);
    BSP_LCD_FillRect(0, 0, BSP_LCD_GetXSize(), 80);
    BSP_LCD_SetTextColor(LCD_COLOR_WHITE);
    BSP_LCD_SetBackColor(LCD_COLOR_BLUE);
    BSP_LCD_SetFont(&Font24);

    if(demoIndex == TOUCHSCREEN_DEMO_1)
    {
      BSP_LCD_DisplayStringAt(0, 0, (uint8_t *)"Touchscreen basic polling", CENTER_MODE);
      BSP_LCD_SetFont(&Font12);
      BSP_LCD_DisplayStringAt(0, 30, (uint8_t *)"Please use the Touchscreen to", CENTER_MODE);
      BSP_LCD_DisplayStringAt(0, 45, (uint8_t *)"activate the colored circle", CENTER_MODE);
      BSP_LCD_DisplayStringAt(0, 60, (uint8_t *)"inside the rectangle. Then press User button", CENTER_MODE);
    }
    else if (demoIndex == TOUCHSCREEN_DEMO_2)
    {
      BSP_LCD_DisplayStringAt(0, 0, (uint8_t *)"Touchscreen dual touch polling", CENTER_MODE);
      BSP_LCD_SetFont(&Font12);
      BSP_LCD_DisplayStringAt(0, 30, (uint8_t *)"Please press the Touchscreen to", CENTER_MODE);
      BSP_LCD_DisplayStringAt(0, 45, (uint8_t *)"activate single and", CENTER_MODE);
      BSP_LCD_DisplayStringAt(0, 60, (uint8_t *)"dual touch", CENTER_MODE);

    }
    else /* demoIndex == TOUCHSCREEN_DEMO_3 */
    {
      BSP_LCD_DisplayStringAt(0, 0, (uint8_t *)"Touchscreen dual touch interrupt", CENTER_MODE);
      BSP_LCD_SetFont(&Font12);
      BSP_LCD_DisplayStringAt(0, 30, (uint8_t *)"Please press the Touchscreen to", CENTER_MODE);
      BSP_LCD_DisplayStringAt(0, 45, (uint8_t *)"activate single and", CENTER_MODE);
      BSP_LCD_DisplayStringAt(0, 60, (uint8_t *)"dual touch", CENTER_MODE);
    }

    /* Set the LCD Text Color */
    BSP_LCD_SetTextColor(LCD_COLOR_BLUE);
    BSP_LCD_DrawRect(10, 90, BSP_LCD_GetXSize() - 20, BSP_LCD_GetYSize() - 100);
    BSP_LCD_DrawRect(11, 91, BSP_LCD_GetXSize() - 22, BSP_LCD_GetYSize() - 102);

  } /* of if(demoIndex <= TOUCHSCREEN_DEMO_MAX) */
}

/**
  * @brief  Draw Touchscreen Background
  * @param  state : touch zone state
  * @retval None
  */
void Touchscreen_DrawBackground_Circles(uint8_t state)
{
  uint16_t x, y;
  switch (state)
  {
    case 0:
      BSP_LCD_SetTextColor(LCD_COLOR_BLUE);
      BSP_LCD_FillCircle(CIRCLE_XPOS(1), CIRCLE_YPOS(1), CIRCLE_RADIUS);

      BSP_LCD_SetTextColor(LCD_COLOR_RED);
      BSP_LCD_FillCircle(CIRCLE_XPOS(2), CIRCLE_YPOS(2), CIRCLE_RADIUS);

      BSP_LCD_SetTextColor(LCD_COLOR_YELLOW);
      BSP_LCD_FillCircle(CIRCLE_XPOS(3), CIRCLE_YPOS(3), CIRCLE_RADIUS);

      BSP_LCD_SetTextColor(LCD_COLOR_GREEN);
      BSP_LCD_FillCircle(CIRCLE_XPOS(4), CIRCLE_YPOS(3), CIRCLE_RADIUS);

      BSP_LCD_SetTextColor(LCD_COLOR_WHITE);
      BSP_LCD_FillCircle(CIRCLE_XPOS(1), CIRCLE_YPOS(1), CIRCLE_RADIUS - 2);
      BSP_LCD_FillCircle(CIRCLE_XPOS(2), CIRCLE_YPOS(2), CIRCLE_RADIUS - 2);
      BSP_LCD_FillCircle(CIRCLE_XPOS(3), CIRCLE_YPOS(3), CIRCLE_RADIUS - 2);
      BSP_LCD_FillCircle(CIRCLE_XPOS(4), CIRCLE_YPOS(3), CIRCLE_RADIUS - 2);
      break;

    case 1:
      BSP_LCD_SetTextColor(LCD_COLOR_BLUE);
      BSP_LCD_FillCircle(CIRCLE_XPOS(1), CIRCLE_YPOS(1), CIRCLE_RADIUS);
      BSP_LCD_SetTextColor(LCD_COLOR_WHITE);
      BSP_LCD_FillCircle(CIRCLE_XPOS(1), CIRCLE_YPOS(1), CIRCLE_RADIUS - 2);
      break;

    case 2:
      BSP_LCD_SetTextColor(LCD_COLOR_RED);
      BSP_LCD_FillCircle(CIRCLE_XPOS(2), CIRCLE_YPOS(2), CIRCLE_RADIUS);
      BSP_LCD_SetTextColor(LCD_COLOR_WHITE);
      BSP_LCD_FillCircle(CIRCLE_XPOS(2), CIRCLE_YPOS(2), CIRCLE_RADIUS - 2);
      break;

    case 4:
      BSP_LCD_SetTextColor(LCD_COLOR_YELLOW);
      BSP_LCD_FillCircle(CIRCLE_XPOS(3), CIRCLE_YPOS(3), CIRCLE_RADIUS);
      BSP_LCD_SetTextColor(LCD_COLOR_WHITE);
      BSP_LCD_FillCircle(CIRCLE_XPOS(3), CIRCLE_YPOS(3), CIRCLE_RADIUS - 2);
      break;

    case 8:
      BSP_LCD_SetTextColor(LCD_COLOR_GREEN);
      BSP_LCD_FillCircle(CIRCLE_XPOS(4), CIRCLE_YPOS(4), CIRCLE_RADIUS);
      BSP_LCD_SetTextColor(LCD_COLOR_WHITE);
      BSP_LCD_FillCircle(CIRCLE_XPOS(4), CIRCLE_YPOS(4), CIRCLE_RADIUS - 2);
      break;

    case 16:
      BSP_LCD_SetTextColor(LCD_COLOR_BLUE);
      BSP_LCD_FillCircle(CIRCLE_XPOS(2), CIRCLE_YPOS(2), CIRCLE_RADIUS);
      BSP_LCD_FillCircle(CIRCLE_XPOS(3), CIRCLE_YPOS(3), CIRCLE_RADIUS);

      BSP_LCD_SetTextColor(LCD_COLOR_WHITE);
      BSP_LCD_FillCircle(CIRCLE_XPOS(2), CIRCLE_YPOS(2), CIRCLE_RADIUS - 2);
      BSP_LCD_FillCircle(CIRCLE_XPOS(3), CIRCLE_YPOS(3), CIRCLE_RADIUS - 2);

      BSP_LCD_SetTextColor(LCD_COLOR_BLUE);
      BSP_LCD_DrawHLine(CIRCLE_XPOS(2)-LINE_LENGHT, CIRCLE_YPOS(2), 2*LINE_LENGHT);
      BSP_LCD_DrawHLine(CIRCLE_XPOS(3)-LINE_LENGHT, CIRCLE_YPOS(3), 2*LINE_LENGHT);
      BSP_LCD_DrawVLine(CIRCLE_XPOS(3), CIRCLE_YPOS(3)-LINE_LENGHT, 2*LINE_LENGHT);

      BSP_LCD_SetTextColor(LCD_COLOR_BLUE);
      BSP_LCD_SetBackColor(LCD_COLOR_WHITE);
      BSP_LCD_SetFont(&Font24);
      x = CIRCLE_XPOS(2) + 20;
      y = CIRCLE_YPOS(2) - CIRCLE_RADIUS - BSP_LCD_GetFont()->Height;
      BSP_LCD_DisplayStringAt(x, y, (uint8_t *)"Volume", LEFT_MODE);
      break;

    case 32:
      BSP_LCD_SetTextColor(LCD_COLOR_BLACK);
      BSP_LCD_FillCircle(CIRCLE_XPOS(1), CIRCLE_YPOS(1), CIRCLE_RADIUS);
      BSP_LCD_FillCircle(CIRCLE_XPOS(2), CIRCLE_YPOS(2), CIRCLE_RADIUS);

      BSP_LCD_SetTextColor(LCD_COLOR_WHITE);
      BSP_LCD_FillCircle(CIRCLE_XPOS(1), CIRCLE_YPOS(1), CIRCLE_RADIUS - 2);
      BSP_LCD_FillCircle(CIRCLE_XPOS(2), CIRCLE_YPOS(2), CIRCLE_RADIUS - 2);

      BSP_LCD_SetTextColor(LCD_COLOR_BLACK);
      BSP_LCD_SetBackColor(LCD_COLOR_WHITE);
      BSP_LCD_SetFont(&Font20);
      x = CIRCLE_XPOS(1) - 10;
      y = CIRCLE_YPOS(1) - (BSP_LCD_GetFont()->Height)/2;
      BSP_LCD_DisplayStringAt(x, y, (uint8_t *)"Up", LEFT_MODE);
      x = CIRCLE_XPOS(2) - 10;
      y = CIRCLE_YPOS(3)  - (BSP_LCD_GetFont()->Height)/2;
      BSP_LCD_DisplayStringAt(x, y, (uint8_t *)"Dw", LEFT_MODE);
      BSP_LCD_SetFont(&Font12);

      break;
  }
}

/**
  * @brief  TouchScreen get touch position
  * @param  None
  * @retval None
  */
uint8_t TouchScreen_GetTouchPosition(void)
{
  uint16_t x1, y1;
  uint8_t circleNr = 0;

  /* Check in polling mode in touch screen the touch status and coordinates */
  /* of touches if touch occurred                                           */
  BSP_TS_GetState(&TS_State);
  if(TS_State.touchDetected)
  {
    /* One or dual touch have been detected          */
    /* Only take into account the first touch so far */

    /* Get X and Y position of the first */
    x1 = TS_State.touchX[0];
    y1 = TS_State.touchY[0];

    if ((y1 > (CIRCLE_YPOS(1) - CIRCLE_RADIUS)) &&
        (y1 < (CIRCLE_YPOS(1) + CIRCLE_RADIUS)))
    {
      if ((x1 > (CIRCLE_XPOS(2) - CIRCLE_RADIUS)) &&
          (x1 < (CIRCLE_XPOS(2) + CIRCLE_RADIUS)))
      {
        circleNr = 1;
      }

      if ((x1 > (CIRCLE_XPOS(3) - CIRCLE_RADIUS)) &&
          (x1 < (CIRCLE_XPOS(3) + CIRCLE_RADIUS)))
      {
        circleNr = 2;
      }
    }
    else
    {
      if (((y1 < 220) && (y1 > 140)) &&
          ((x1 < 160) && (x1 > 100)))
      {
        circleNr = 0xFE;   /* top part of the screen */
      }
      else
      {
        circleNr = 0xFF;
      }
    }
  } /* of if(TS_State.TouchDetected) */
  return circleNr;
}

/**
  * @brief  Check for user input
  * @param  None
* @retval Input state (1 : active / 0 : Inactive)
  */
uint8_t CheckForUserInput(void)
{
  if(BSP_PB_GetState(BUTTON_WAKEUP) == GPIO_PIN_SET)
  {
    while (BSP_PB_GetState(BUTTON_WAKEUP) == GPIO_PIN_SET);
    return 1 ;
  }
  return 0;
}

/* USER CODE END 4 */

void Error_Handler(void)
{
  __disable_irq();
  while (1)
  {
  }
}

/************************ (C) COPYRIGHT STMicroelectronics *****END OF FILE****/
